VERSION ""

NS_ :

BS_:

BU_: Vector__XXX ECU SenderNode

BO_ 1039 ACC_MMI_R1: 5 Vector__XXX
 SG_ SelectedDistanceDisplayRequest : 1|2@0+ (1.0,0.0) [0|0] "" Vector__XXX
 SG_ DistanceOverrideDisplayRequest : 2|1@0+ (1.0,0.0) [0|0] "" Vector__XXX
 SG_ SpeedOverrideDisplayRequest : 3|1@0+ (1.0,0.0) [0|0] "" Vector__XXX
 SG_ ACCLSF_StatusDisplay : 7|4@0+ (1.0,0.0) [0|0] "" Vector__XXX
 SG_ ACCRequestedSpeedDisplayRequest : 15|8@0+ (1.0,0.0) [0|0] "" Vector__XXX
 SG_ DriverTakeOverDisplayRequest : 18|3@0+ (1.0,0.0) [0|0] "" Vector__XXX
 SG_ AEBS_FailureDisplayRequest : 19|1@0+ (1.0,0.0) [0|0] "" Vector__XXX
 SG_ AEBS_DangerAlert : 20|1@0+ (1.0,0.0) [0|0] "" Vector__XXX
 SG_ DetectedTargetDisplayRequest_TM : 23|3@0+ (1.0,0.0) [0|0] "" Vector__XXX
 SG_ DW_ActivationState_TM : 24|1@0+ (1.0,0.0) [0|0] "" Vector__XXX
 SG_ DW_FollowUpTimeDisplay_TM : 30|6@0+ (1.0,0.0) [0|0] "" Vector__XXX
 SG_ AEBS_DistanceWarning : 31|1@0+ (1.0,0.0) [0|0] "" Vector__XXX
 SG_ AEBS_TemporarlyFailureDisplay : 33|2@0+ (1.0,0.0) [0|0] "" Vector__XXX
 SG_ AEBS_PedestrianAlert : 35|2@0+ (1.0,0.0) [0|0] "" Vector__XXX
 SG_ SpeedNotRelevantDisplayRequest : 37|2@0+ (1.0,0.0) [0|0] "" Vector__XXX
 SG_ FollowUpTimeBlinkRequest_TM : 38|1@0+ (1.0,0.0) [0|0] "" Vector__XXX
 SG_ FCW_ActivationState : 39|1@0+ (1.0,0.0) [0|0] "" Vector__XXX

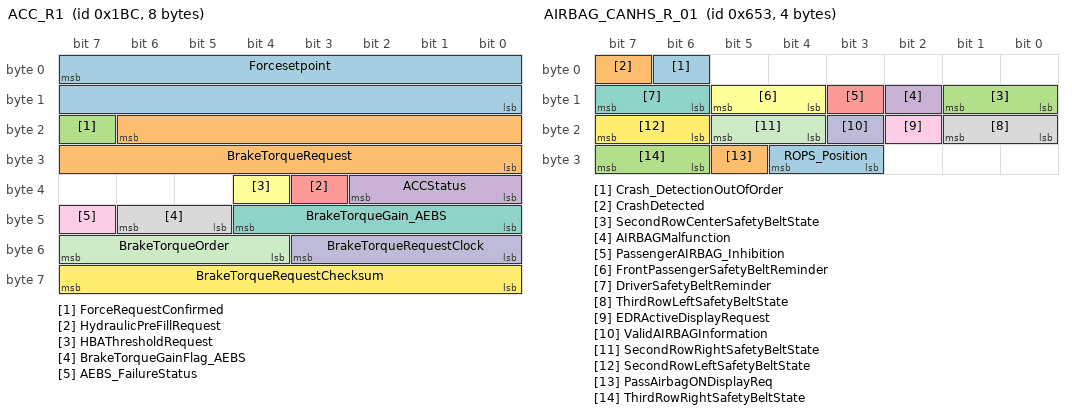
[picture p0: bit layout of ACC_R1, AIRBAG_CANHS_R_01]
BO_ 444 ACC_R1: 8 Vector__XXX
 SG_ Forcesetpoint : 7|16@0+ (1.0,0.0) [0|0] "" Vector__XXX
 SG_ BrakeTorqueRequest : 22|15@0+ (1.0,0.0) [0|0] "Nm" Vector__XXX
 SG_ ForceRequestConfirmed : 23|1@0+ (1.0,0.0) [0|0] "" Vector__XXX
 SG_ ACCStatus : 34|3@0+ (1.0,0.0) [0|0] "" Vector__XXX
 SG_ HydraulicPreFillRequest : 35|1@0+ (1.0,0.0) [0|0] "" Vector__XXX
 SG_ HBAThresholdRequest : 36|1@0+ (1.0,0.0) [0|0] "" Vector__XXX
 SG_ BrakeTorqueGain_AEBS : 44|5@0+ (0.05,1.0) [0|0] "" Vector__XXX
 SG_ BrakeTorqueGainFlag_AEBS : 46|2@0+ (1.0,0.0) [0|0] "" Vector__XXX
 SG_ AEBS_FailureStatus : 47|1@0+ (1.0,0.0) [0|0] "" Vector__XXX
 SG_ BrakeTorqueRequestClock : 51|4@0+ (1.0,0.0) [0|0] "" Vector__XXX
 SG_ BrakeTorqueOrder : 55|4@0+ (1.0,0.0) [0|0] "" Vector__XXX
 SG_ BrakeTorqueRequestChecksum : 63|8@0+ (1.0,0.0) [0|0] "" Vector__XXX

BO_ 1917 ACC_to_DTOOL: 8 Vector__XXX
 SG_ ACC_to_DTOOL : 7|64@0+ (1.0,0.0) [0|0] "" Vector__XXX

BO_ 35 AIRBAGCrash: 2 Vector__XXX
 SG_ AirbagCrashOrder : 7|16@0+ (1.0,0.0) [0|0] "" Vector__XXX

BO_ 1619 AIRBAG_CANHS_R_01: 4 Vector__XXX
 SG_ Crash_DetectionOutOfOrder : 6|1@0+ (1.0,0.0) [0|0] "" Vector__XXX
 SG_ CrashDetected : 7|1@0+ (1.0,0.0) [0|0] "" Vector__XXX
 SG_ SecondRowCenterSafetyBeltState : 9|2@0+ (1.0,0.0) [0|0] "" Vector__XXX
 SG_ AIRBAGMalfunction : 10|1@0+ (1.0,0.0) [0|0] "" Vector__XXX
 SG_ PassengerAIRBAG_Inhibition : 11|1@0+ (1.0,0.0) [0|0] "" Vector__XXX
 SG_ FrontPassengerSafetyBeltReminder : 13|2@0+ (1.0,0.0) [0|0] "" Vector__XXX
 SG_ DriverSafetyBeltReminder : 15|2@0+ (1.0,0.0) [0|0] "" Vector__XXX
 SG_ ThirdRowLeftSafetyBeltState : 17|2@0+ (1.0,0.0) [0|0] "" Vector__XXX
 SG_ EDRActiveDisplayRequest : 18|1@0+ (1.0,0.0) [0|0] "" Vector__XXX
 SG_ ValidAIRBAGInformation : 19|1@0+ (1.0,0.0) [0|0] "" Vector__XXX
 SG_ SecondRowRightSafetyBeltState : 21|2@0+ (1.0,0.0) [0|0] "" Vector__XXX
 SG_ SecondRowLeftSafetyBeltState : 23|2@0+ (1.0,0.0) [0|0] "" Vector__XXX
 SG_ ROPS_Position : 28|2@0+ (1.0,0.0) [0|0] "" Vector__XXX
 SG_ PassAirbagONDisplayReq : 29|1@0+ (1.0,0.0) [0|0] "" Vector__XXX
 SG_ ThirdRowRightSafetyBeltState : 31|2@0+ (1.0,0.0) [0|0] "" Vector__XXX

BO_ 1906 AIRBAG_to_DTOOL: 8 Vector__XXX
 SG_ AIRBAG_to_DTOOL : 7|64@0+ (1.0,0.0) [0|0] "" Vector__XXX

BO_ 1954 AMPLI_to_DTOOL: 8 Vector__XXX
 SG_ AMPLI_to_DTOOL : 7|64@0+ (1.0,0.0) [0|0] "" Vector__XXX

BO_ 2025 AT_to_DTOOL: 8 Vector__XXX
 SG_ AT_to_DTOOL : 7|64@0+ (1.0,0.0) [0|0] "" Vector__XXX

BO_ 1939 BCB_to_DTOOL: 8 Vector__XXX
 SG_ BCB_to_DTOOL : 7|64@0+ (1.0,0.0) [0|0] "" Vector__XXX

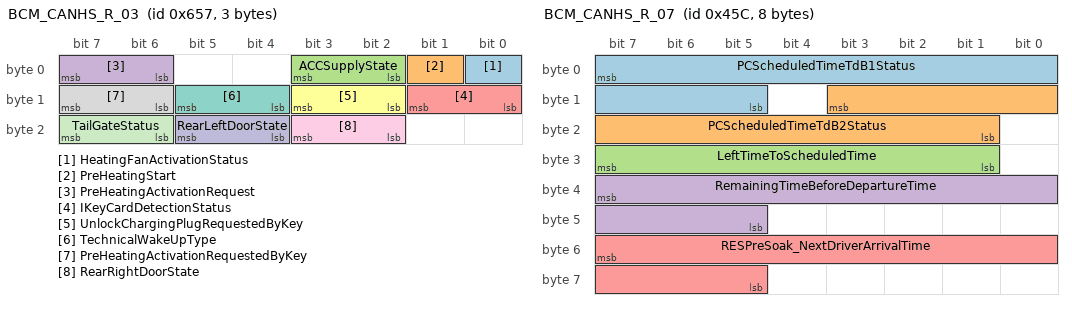
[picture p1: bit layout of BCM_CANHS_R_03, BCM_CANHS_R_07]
BO_ 1623 BCM_CANHS_R_03: 3 Vector__XXX
 SG_ HeatingFanActivationStatus : 0|1@0+ (1.0,0.0) [0|0] "" Vector__XXX
 SG_ PreHeatingStart : 1|1@0+ (1.0,0.0) [0|0] "" Vector__XXX
 SG_ ACCSupplyState : 3|2@0+ (1.0,0.0) [0|0] "" Vector__XXX
 SG_ PreHeatingActivationRequest : 7|2@0+ (1.0,0.0) [0|0] "" Vector__XXX
 SG_ IKeyCardDetectionStatus : 9|2@0+ (1.0,0.0) [0|0] "" Vector__XXX
 SG_ UnlockChargingPlugRequestedByKey : 11|2@0+ (1.0,0.0) [0|0] "" Vector__XXX
 SG_ TechnicalWakeUpType : 13|2@0+ (1.0,0.0) [0|0] "" Vector__XXX
 SG_ PreHeatingActivationRequestedByKey : 15|2@0+ (1.0,0.0) [0|0] "" Vector__XXX
 SG_ RearRightDoorState : 19|2@0+ (1.0,0.0) [0|0] "" Vector__XXX
 SG_ RearLeftDoorState : 21|2@0+ (1.0,0.0) [0|0] "" Vector__XXX
 SG_ TailGateStatus : 23|2@0+ (1.0,0.0) [0|0] "" Vector__XXX

BO_ 848 BCM_CANHS_R_04: 8 Vector__XXX
 SG_ VehicleStateExtented : 3|4@0+ (1.0,0.0) [0|0] "" Vector__XXX
 SG_ StartAutoSystemFailure : 5|2@0+ (1.0,0.0) [0|0] "" Vector__XXX
 SG_ BCM_WakeUpSleepCommand : 7|2@0+ (1.0,0.0) [0|0] "" Vector__XXX
 SG_ AbsoluteTimeSince1rstIgnition : 15|24@0+ (1.0,0.0) [0|0] "mn" Vector__XXX
 SG_ LightsRequest : 33|2@0+ (1.0,0.0) [0|0] "" Vector__XXX
 SG_ TailGateStatus : 35|2@0+ (1.0,0.0) [0|0] "" Vector__XXX
 SG_ TailGateButtonPushed : 37|2@0+ (1.0,0.0) [0|0] "" Vector__XXX
 SG_ FlashingIndicatorCommandPosition : 41|2@0+ (1.0,0.0) [0|0] "" Vector__XXX
 SG_ GenericApplicativeDiagEnable : 43|2@0+ (1.0,0.0) [0|0] "" Vector__XXX
 SG_ BrakeInfoStatus : 46|3@0+ (1.0,0.0) [0|0] "" Vector__XXX
 SG_ DiagMuxOn_BCM : 47|1@0+ (1.0,0.0) [0|0] "" Vector__XXX
 SG_ NeutralSwitchFaultDisplay : 48|1@0+ (1.0,0.0) [0|0] "" Vector__XXX
 SG_ VehicleOutsideLockedState : 49|1@0+ (1.0,0.0) [0|0] "" Vector__XXX
 SG_ PassengerDoorState : 51|2@0+ (1.0,0.0) [0|0] "" Vector__XXX
 SG_ DriverDoorState : 53|2@0+ (1.0,0.0) [0|0] "" Vector__XXX
 SG_ EngineHoodState : 55|2@0+ (1.0,0.0) [0|0] "" Vector__XXX
 SG_ RearRightDoorState : 57|2@0+ (1.0,0.0) [0|0] "" Vector__XXX
 SG_ RearLeftDoorState : 59|2@0+ (1.0,0.0) [0|0] "" Vector__XXX
 SG_ WarningLightsStatus : 60|1@0+ (1.0,0.0) [0|0] "" Vector__XXX
 SG_ WakeUpType : 61|1@0+ (1.0,0.0) [0|0] "" Vector__XXX
 SG_ EcoModeRequest : 63|2@0+ (1.0,0.0) [0|0] "" Vector__XXX

BO_ 1373 BCM_CANHS_R_05: 8 Vector__XXX
 SG_ Blower_StateBCM : 0|1@0+ (1.0,0.0) [0|0] "" Vector__XXX
 SG_ BrakeSwitchFailure : 2|2@0+ (1.0,0.0) [0|0] "" Vector__XXX
 SG_ ElectricalPowerDrived : 7|5@0+ (100.0,0.0) [0|0] "W" Vector__XXX
 SG_ FrontWashingRequest : 9|2@0+ (1.0,0.0) [0|0] "" Vector__XXX
 SG_ NeutralContact : 11|2@0+ (1.0,0.0) [0|0] "" Vector__XXX
 SG_ RearGearEngaged : 13|2@0+ (1.0,0.0) [0|0] "" Vector__XXX
 SG_ KeyVehicle : 15|2@0+ (1.0,0.0) [0|0] "" Vector__XXX
 SG_ PTC_Thermal_Regulator_Freeze : 16|1@0+ (1.0,0.0) [0|0] "" Vector__XXX
 SG_ PTCEngineIdleSpeedRequest : 17|1@0+ (1.0,0.0) [0|0] "" Vector__XXX
 SG_ DischargedBatTempoRequest : 18|1@0+ (1.0,0.0) [0|0] "" Vector__XXX
 SG_ RearDefrostEngaged : 19|1@0+ (1.0,0.0) [0|0] "" Vector__XXX
 SG_ ClutchSwitchMinimumTravel : 21|2@0+ (1.0,0.0) [0|0] "" Vector__XXX
 SG_ ClutchSwitchMaximumTravel : 23|2@0+ (1.0,0.0) [0|0] "" Vector__XXX
 SG_ MinimumVoltagebyBCM : 27|4@0+ (1.0,0.0) [0|0] "" Vector__XXX
 SG_ StarterStatus : 29|2@0+ (1.0,0.0) [0|0] "" Vector__XXX
 SG_ ParkingBrakeStatus : 31|2@0+ (1.0,0.0) [0|0] "" Vector__XXX
 SG_ CustomerDeparture : 33|2@0+ (1.0,0.0) [0|0] "" Vector__XXX
 SG_ PTCState : 35|2@0+ (1.0,0.0) [0|0] "" Vector__XXX
 SG_ AutoStartFailure : 37|2@0+ (1.0,0.0) [0|0] "" Vector__XXX
 SG_ StarterInhibtion : 39|2@0+ (1.0,0.0) [0|0] "" Vector__XXX
 SG_ DeliveryModeInformation_v2 : 41|2@0+ (1.0,0.0) [0|0] "" Vector__XXX
 SG_ FuelBurnerActivationState : 42|1@0+ (1.0,0.0) [0|0] "" Vector__XXX
 SG_ BCM_SailingIdleForbidden : 44|2@0+ (1.0,0.0) [0|0] "" Vector__XXX
 SG_ HighBeamState : 45|1@0+ (1.0,0.0) [0|0] "" Vector__XXX
 SG_ LowBeamState : 46|1@0+ (1.0,0.0) [0|0] "" Vector__XXX
 SG_ DisplayRequest : 47|1@0+ (1.0,0.0) [0|0] "" Vector__XXX
 SG_ ClimateCoolingRequest : 48|1@0+ (1.0,0.0) [0|0] "" Vector__XXX
 SG_ UserIdentification : 51|3@0+ (1.0,0.0) [0|0] "" Vector__XXX
 SG_ DayNightStatusSynth : 53|1@0+ (1.0,0.0) [0|0] "" Vector__XXX
 SG_ InternalLightingActivationState : 54|1@0+ (1.0,0.0) [0|0] "" Vector__XXX
 SG_ DeliveryModeInformation : 55|1@0+ (1.0,0.0) [0|0] "" Vector__XXX
 SG_ DriverDoorLockedStatus : 56|1@0+ (1.0,0.0) [0|0] "" Vector__XXX
 SG_ RKEButtonPressed : 60|4@0+ (1.0,0.0) [0|0] "" Vector__XXX
 SG_ FrontDefrostEngaged : 61|1@0+ (1.0,0.0) [0|0] "" Vector__XXX
 SG_ StartingRequest_EV : 63|2@0+ (1.0,0.0) [0|0] "" Vector__XXX

BO_ 1116 BCM_CANHS_R_07: 8 Vector__XXX
 SG_ PCScheduledTimeTdB1Status : 7|11@0+ (1.0,0.0) [0|0] "min" Vector__XXX
 SG_ PCScheduledTimeTdB2Status : 11|11@0+ (1.0,0.0) [0|0] "min" Vector__XXX
 SG_ LeftTimeToScheduledTime : 31|7@0+ (1.0,0.0) [0|0] "min" Vector__XXX
 SG_ RemainingTimeBeforeDepartureTime : 39|11@0+ (1.0,0.0) [0|0] "min" Vector__XXX
 SG_ RESPreSoak_NextDriverArrivalTime : 55|11@0+ (1.0,0.0) [0|0] "min" Vector__XXX

BO_ 1196 BCM_CANHS_R_08: 6 Vector__XXX
 SG_ GearboxChangeOnCrankingRequest : 1|2@0+ (1.0,0.0) [0|0] "" Vector__XXX
 SG_ Reserved_1bit : 2|1@0+ (1.0,0.0) [0|0] "" Vector__XXX
 SG_ DirectionSideConfirmation : 3|1@0+ (1.0,0.0) [0|0] "" Vector__XXX
 SG_ VehicleActivationState : 6|3@0+ (1.0,0.0) [0|0] "" Vector__XXX
 SG_ CustomerAutoStartWill : 7|1@0+ (1.0,0.0) [0|0] "" Vector__XXX
 SG_ BatteryVoltage_V2 : 15|8@0+ (0.06,6.0) [0|0] "V" Vector__XXX
 SG_ SOCBattery14V_BCM : 21|6@0+ (0.5,69.0) [0|0] "%" Vector__XXX
 SG_ BCM_StopAutoForbidden : 23|2@0+ (1.0,0.0) [0|0] "" Vector__XXX
 SG_ DriverDoorStatusSupposedFailure : 24|1@0+ (1.0,0.0) [0|0] "" Vector__XXX
 SG_ BattWarnReq_Level_Lo_BCM : 25|1@0+ (1.0,0.0) [0|0] "" Vector__XXX
 SG_ BattWarnReq_Level_Hi_BCM : 26|1@0+ (1.0,0.0) [0|0] "" Vector__XXX
 SG_ Battery14VCSensorFailureStatus : 27|1@0+ (1.0,0.0) [0|0] "" Vector__XXX
 SG_ StopStartSwitch : 29|2@0+ (1.0,0.0) [0|0] "" Vector__XXX
 SG_ BatterySetPointGeneratorStatus : 31|2@0+ (1.0,0.0) [0|0] "" Vector__XXX
 SG_ TailGateStatusSupposedFailure : 32|1@0+ (1.0,0.0) [0|0] "" Vector__XXX
 SG_ AuthorizationPH : 34|2@0+ (1.0,0.0) [0|0] "" Vector__XXX
 SG_ EEM_SailingIdleForbidden : 36|2@0+ (1.0,0.0) [0|0] "" Vector__XXX
 SG_ IgnitionSupplyConfirmation_BCM : 37|1@0+ (1.0,0.0) [0|0] "" Vector__XXX
 SG_ IdleSpeedInhibitionRequest_BCM : 39|2@0+ (1.0,0.0) [0|0] "" Vector__XXX
 SG_ HornRequest : 44|3@0+ (1.0,0.0) [0|0] "" Vector__XXX
 SG_ RemoteLight_BCM : 45|1@0+ (1.0,0.0) [0|0] "" Vector__XXX
 SG_ WindowsLiftAuthorization : 47|2@0+ (1.0,0.0) [0|0] "" Vector__XXX

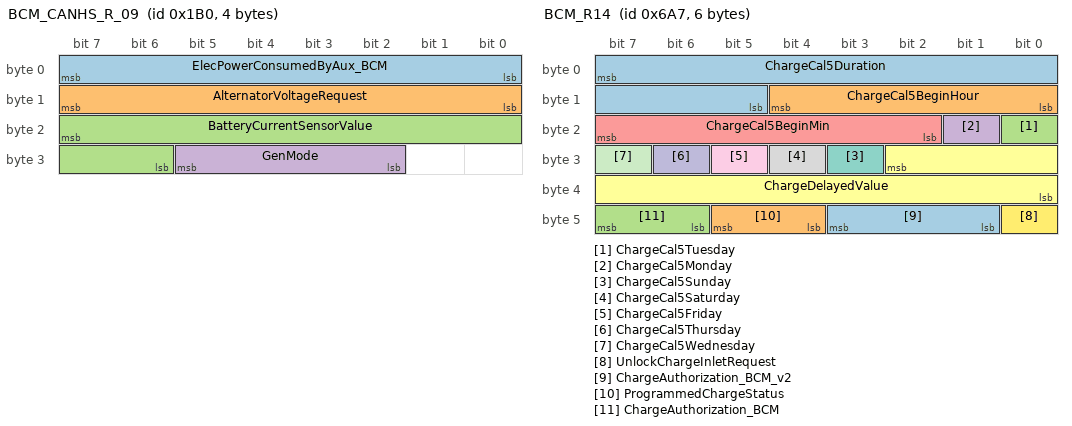
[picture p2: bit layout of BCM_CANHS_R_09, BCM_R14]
BO_ 432 BCM_CANHS_R_09: 4 Vector__XXX
 SG_ ElecPowerConsumedByAux_BCM : 7|8@0+ (40.0,0.0) [0|0] "W" Vector__XXX
 SG_ AlternatorVoltageRequest : 15|8@0+ (0.025,10.6) [0|0] "V" Vector__XXX
 SG_ BatteryCurrentSensorValue : 23|10@0- (1.0,-320.0) [0|0] "A" Vector__XXX
 SG_ GenMode : 29|4@0+ (1.0,0.0) [0|0] "" Vector__XXX

BO_ 1700 BCM_R12: 8 Vector__XXX
 SG_ ChargeCal1Duration : 7|11@0+ (1.0,0.0) [0|0] "min" Vector__XXX
 SG_ ChargeCal1BeginHour : 12|5@0+ (1.0,0.0) [0|0] "h" Vector__XXX
 SG_ ChargeCal1Tuesday : 16|1@0+ (1.0,0.0) [0|0] "" Vector__XXX
 SG_ ChargeCal1Monday : 17|1@0+ (1.0,0.0) [0|0] "" Vector__XXX
 SG_ ChargeCal1BeginMin : 23|6@0+ (1.0,0.0) [0|0] "min" Vector__XXX
 SG_ ZEnSwitchState : 26|1@0+ (1.0,0.0) [0|0] "" Vector__XXX
 SG_ ChargeCal1Sunday : 27|1@0+ (1.0,0.0) [0|0] "" Vector__XXX
 SG_ ChargeCal1Saturday : 28|1@0+ (1.0,0.0) [0|0] "" Vector__XXX
 SG_ ChargeCal1Friday : 29|1@0+ (1.0,0.0) [0|0] "" Vector__XXX
 SG_ ChargeCal1Thursday : 30|1@0+ (1.0,0.0) [0|0] "" Vector__XXX
 SG_ ChargeCal1Wednesday : 31|1@0+ (1.0,0.0) [0|0] "" Vector__XXX
 SG_ ChargeCal2Duration : 39|11@0+ (1.0,0.0) [0|0] "min" Vector__XXX
 SG_ ChargeCal2BeginHour : 44|5@0+ (1.0,0.0) [0|0] "h" Vector__XXX
 SG_ ChargeCal2Tuesday : 48|1@0+ (1.0,0.0) [0|0] "" Vector__XXX
 SG_ ChargeCal2Monday : 49|1@0+ (1.0,0.0) [0|0] "" Vector__XXX
 SG_ ChargeCal2BeginMin : 55|6@0+ (1.0,0.0) [0|0] "min" Vector__XXX
 SG_ ChargeCal2Sunday : 59|1@0+ (1.0,0.0) [0|0] "" Vector__XXX
 SG_ ChargeCal2Saturday : 60|1@0+ (1.0,0.0) [0|0] "" Vector__XXX
 SG_ ChargeCal2Friday : 61|1@0+ (1.0,0.0) [0|0] "" Vector__XXX
 SG_ ChargeCal2Thursday : 62|1@0+ (1.0,0.0) [0|0] "" Vector__XXX
 SG_ ChargeCal2Wednesday : 63|1@0+ (1.0,0.0) [0|0] "" Vector__XXX

BO_ 1702 BCM_R13: 8 Vector__XXX
 SG_ ChargeCal3Duration : 7|11@0+ (1.0,0.0) [0|0] "min" Vector__XXX
 SG_ ChargeCal3BeginHour : 12|5@0+ (1.0,0.0) [0|0] "h" Vector__XXX
 SG_ ChargeCal3Tuesday : 16|1@0+ (1.0,0.0) [0|0] "" Vector__XXX
 SG_ ChargeCal3Monday : 17|1@0+ (1.0,0.0) [0|0] "" Vector__XXX
 SG_ ChargeCal3BeginMin : 23|6@0+ (1.0,0.0) [0|0] "min" Vector__XXX
 SG_ ChargeCal3Sunday : 27|1@0+ (1.0,0.0) [0|0] "" Vector__XXX
 SG_ ChargeCal3Saturday : 28|1@0+ (1.0,0.0) [0|0] "" Vector__XXX
 SG_ ChargeCal3Friday : 29|1@0+ (1.0,0.0) [0|0] "" Vector__XXX
 SG_ ChargeCal3Thursday : 30|1@0+ (1.0,0.0) [0|0] "" Vector__XXX
 SG_ ChargeCal3Wednesday : 31|1@0+ (1.0,0.0) [0|0] "" Vector__XXX
 SG_ ChargeCal4Duration : 39|11@0+ (1.0,0.0) [0|0] "min" Vector__XXX
 SG_ ChargeCal4BeginHour : 44|5@0+ (1.0,0.0) [0|0] "h" Vector__XXX
 SG_ ChargeCal4Tuesday : 48|1@0+ (1.0,0.0) [0|0] "" Vector__XXX
 SG_ ChargeCal4Monday : 49|1@0+ (1.0,0.0) [0|0] "" Vector__XXX
 SG_ ChargeCal4BeginMin : 55|6@0+ (1.0,0.0) [0|0] "min" Vector__XXX
 SG_ ChargeCal4Sunday : 59|1@0+ (1.0,0.0) [0|0] "" Vector__XXX
 SG_ ChargeCal4Saturday : 60|1@0+ (1.0,0.0) [0|0] "" Vector__XXX
 SG_ ChargeCal4Friday : 61|1@0+ (1.0,0.0) [0|0] "" Vector__XXX
 SG_ ChargeCal4Thursday : 62|1@0+ (1.0,0.0) [0|0] "" Vector__XXX
 SG_ ChargeCal4Wednesday : 63|1@0+ (1.0,0.0) [0|0] "" Vector__XXX

BO_ 1703 BCM_R14: 6 Vector__XXX
 SG_ ChargeCal5Duration : 7|11@0+ (1.0,0.0) [0|0] "min" Vector__XXX
 SG_ ChargeCal5BeginHour : 12|5@0+ (1.0,0.0) [0|0] "h" Vector__XXX
 SG_ ChargeCal5Tuesday : 16|1@0+ (1.0,0.0) [0|0] "" Vector__XXX
 SG_ ChargeCal5Monday : 17|1@0+ (1.0,0.0) [0|0] "" Vector__XXX
 SG_ ChargeCal5BeginMin : 23|6@0+ (1.0,0.0) [0|0] "min" Vector__XXX
 SG_ ChargeDelayedValue : 26|11@0+ (1.0,0.0) [0|0] "min" Vector__XXX
 SG_ ChargeCal5Sunday : 27|1@0+ (1.0,0.0) [0|0] "" Vector__XXX
 SG_ ChargeCal5Saturday : 28|1@0+ (1.0,0.0) [0|0] "" Vector__XXX
 SG_ ChargeCal5Friday : 29|1@0+ (1.0,0.0) [0|0] "" Vector__XXX
 SG_ ChargeCal5Thursday : 30|1@0+ (1.0,0.0) [0|0] "" Vector__XXX
 SG_ ChargeCal5Wednesday : 31|1@0+ (1.0,0.0) [0|0] "" Vector__XXX
 SG_ UnlockChargeInletRequest : 40|1@0+ (1.0,0.0) [0|0] "" Vector__XXX
 SG_ ChargeAuthorization_BCM_v2 : 43|3@0+ (1.0,0.0) [0|0] "" Vector__XXX
 SG_ ProgrammedChargeStatus : 45|2@0+ (1.0,0.0) [0|0] "" Vector__XXX
 SG_ ChargeAuthorization_BCM : 47|2@0+ (1.0,0.0) [0|0] "" Vector__XXX

BO_ 1705 BCM_R15: 7 Vector__XXX
 SG_ PreSoakCal1ArrivalHour : 1|5@0+ (1.0,0.0) [0|0] "h" Vector__XXX
 SG_ PreSoakCal1ArrivalMin : 7|6@0+ (1.0,0.0) [0|0] "min" Vector__XXX
 SG_ PreSoakCal1Friday : 8|1@0+ (1.0,0.0) [0|0] "" Vector__XXX
 SG_ PreSoakCal1Thursday : 9|1@0+ (1.0,0.0) [0|0] "" Vector__XXX
 SG_ PreSoakCal1Wednesday : 10|1@0+ (1.0,0.0) [0|0] "" Vector__XXX
 SG_ PreSoakCal1Tuesday : 11|1@0+ (1.0,0.0) [0|0] "" Vector__XXX
 SG_ PreSoakCal1Monday : 12|1@0+ (1.0,0.0) [0|0] "" Vector__XXX
 SG_ PreSoakCal2ArrivalMin : 21|6@0+ (1.0,0.0) [0|0] "min" Vector__XXX
 SG_ PreSoakCal1Sunday : 22|1@0+ (1.0,0.0) [0|0] "" Vector__XXX
 SG_ PreSoakCal1Saturday : 23|1@0+ (1.0,0.0) [0|0] "" Vector__XXX
 SG_ PreSoakCal2Wednesday : 24|1@0+ (1.0,0.0) [0|0] "" Vector__XXX
 SG_ PreSoakCal2Tuesday : 25|1@0+ (1.0,0.0) [0|0] "" Vector__XXX
 SG_ PreSoakCal2Monday : 26|1@0+ (1.0,0.0) [0|0] "" Vector__XXX
 SG_ PreSoakCal2ArrivalHour : 31|5@0+ (1.0,0.0) [0|0] "h" Vector__XXX
 SG_ PreSoakCal3ArrivalMin : 35|6@0+ (1.0,0.0) [0|0] "min" Vector__XXX
 SG_ PreSoakCal2Sunday : 36|1@0+ (1.0,0.0) [0|0] "" Vector__XXX
 SG_ PreSoakCal2Saturday : 37|1@0+ (1.0,0.0) [0|0] "" Vector__XXX
 SG_ PreSoakCal2Friday : 38|1@0+ (1.0,0.0) [0|0] "" Vector__XXX
 SG_ PreSoakCal2Thursday : 39|1@0+ (1.0,0.0) [0|0] "" Vector__XXX
 SG_ PreSoakCal3Monday : 40|1@0+ (1.0,0.0) [0|0] "" Vector__XXX
 SG_ PreSoakCal3ArrivalHour : 45|5@0+ (1.0,0.0) [0|0] "h" Vector__XXX
 SG_ PreSoakCal3Sunday : 50|1@0+ (1.0,0.0) [0|0] "" Vector__XXX
 SG_ PreSoakCal3Saturday : 51|1@0+ (1.0,0.0) [0|0] "" Vector__XXX
 SG_ PreSoakCal3Friday : 52|1@0+ (1.0,0.0) [0|0] "" Vector__XXX
 SG_ PreSoakCal3Thursday : 53|1@0+ (1.0,0.0) [0|0] "" Vector__XXX
 SG_ PreSoakCal3Wednesday : 54|1@0+ (1.0,0.0) [0|0] "" Vector__XXX
 SG_ PreSoakCal3Tuesday : 55|1@0+ (1.0,0.0) [0|0] "" Vector__XXX

BO_ 1706 BCM_R16: 5 Vector__XXX
 SG_ PreSoakCal4ArrivalHour : 1|5@0+ (1.0,0.0) [0|0] "h" Vector__XXX
 SG_ PreSoakCal4ArrivalMin : 7|6@0+ (1.0,0.0) [0|0] "min" Vector__XXX
 SG_ PreSoakCal4Friday : 8|1@0+ (1.0,0.0) [0|0] "" Vector__XXX
 SG_ PreSoakCal4Thursday : 9|1@0+ (1.0,0.0) [0|0] "" Vector__XXX
 SG_ PreSoakCal4Wednesday : 10|1@0+ (1.0,0.0) [0|0] "" Vector__XXX
 SG_ PreSoakCal4Tuesday : 11|1@0+ (1.0,0.0) [0|0] "" Vector__XXX
 SG_ PreSoakCal4Monday : 12|1@0+ (1.0,0.0) [0|0] "" Vector__XXX
 SG_ PreSoakCal5ArrivalMin : 21|6@0+ (1.0,0.0) [0|0] "min" Vector__XXX
 SG_ PreSoakCal4Sunday : 22|1@0+ (1.0,0.0) [0|0] "" Vector__XXX
 SG_ PreSoakCal4Saturday : 23|1@0+ (1.0,0.0) [0|0] "" Vector__XXX
 SG_ PreSoakCal5Wednesday : 24|1@0+ (1.0,0.0) [0|0] "" Vector__XXX
 SG_ PreSoakCal5Tuesday : 25|1@0+ (1.0,0.0) [0|0] "" Vector__XXX
 SG_ PreSoakCal5Monday : 26|1@0+ (1.0,0.0) [0|0] "" Vector__XXX
 SG_ PreSoakCal5ArrivalHour : 31|5@0+ (1.0,0.0) [0|0] "h" Vector__XXX
 SG_ PreSoakCal5Sunday : 36|1@0+ (1.0,0.0) [0|0] "" Vector__XXX
 SG_ PreSoakCal5Saturday : 37|1@0+ (1.0,0.0) [0|0] "" Vector__XXX
 SG_ PreSoakCal5Friday : 38|1@0+ (1.0,0.0) [0|0] "" Vector__XXX
 SG_ PreSoakCal5Thursday : 39|1@0+ (1.0,0.0) [0|0] "" Vector__XXX

BO_ 1280 BCM_VERLOG: 5 Vector__XXX
 SG_ SLockValueControl : 4|5@0+ (1.0,0.0) [0|0] "" Vector__XXX
 SG_ SoftwareLockValue : 15|32@0+ (1.0,0.0) [0|0] "" Vector__XXX

BO_ 1893 BCM_to_DTOOL: 8 Vector__XXX
 SG_ BCM_to_DTOOL : 7|64@0+ (1.0,0.0) [0|0] "" Vector__XXX

BO_ 1844 BIC_to_DTOOL: 8 Vector__XXX
 SG_ BIC_to_DTOOL : 7|64@0+ (1.0,0.0) [0|0] "" Vector__XXX

BO_ 578 BRAKE_CANHS_RNr_01: 8 Vector__XXX
 SG_ MSRinRegulation : 0|1@0+ (1.0,0.0) [0|0] "" Vector__XXX
 SG_ AYCMalfunction : 1|1@0+ (1.0,0.0) [0|0] "" Vector__XXX
 SG_ AYCinRegulation : 2|1@0+ (1.0,0.0) [0|0] "" Vector__XXX
 SG_ HSAMalfunction : 3|1@0+ (1.0,0.0) [0|0] "" Vector__XXX
 SG_ ASRMalfunction : 4|1@0+ (1.0,0.0) [0|0] "" Vector__XXX
 SG_ ASRinRegulation : 5|1@0+ (1.0,0.0) [0|0] "" Vector__XXX
 SG_ ABSMalfunction : 6|1@0+ (1.0,0.0) [0|0] "" Vector__XXX
 SG_ ABSinRegulation : 7|1@0+ (1.0,0.0) [0|0] "" Vector__XXX
 SG_ ESP_TorqueControlType : 10|3@0+ (1.0,0.0) [0|0] "" Vector__XXX
 SG_ ESP_Clock : 14|4@0+ (1.0,0.0) [0|0] "" Vector__XXX
 SG_ MSRMalfunction : 15|1@0+ (1.0,0.0) [0|0] "" Vector__XXX
 SG_ ASRDynamicTorqueRequest : 23|12@0- (0.5,-400.0) [0|0] "Nm" Vector__XXX
 SG_ ASRStaticTorqueRequest : 27|12@0- (0.5,-400.0) [0|0] "Nm" Vector__XXX
 SG_ MSRTorqueRequest : 47|12@0- (0.5,-400.0) [0|0] "Nm" Vector__XXX
 SG_ HSA_ActivationState : 49|2@0+ (1.0,0.0) [0|0] "" Vector__XXX
 SG_ ShiftingAuthorization : 51|2@0+ (1.0,0.0) [0|0] "" Vector__XXX
 SG_ CRC_BRAKE_CANHS_RNr_01 : 63|8@0+ (1.0,0.0) [0|0] "" Vector__XXX

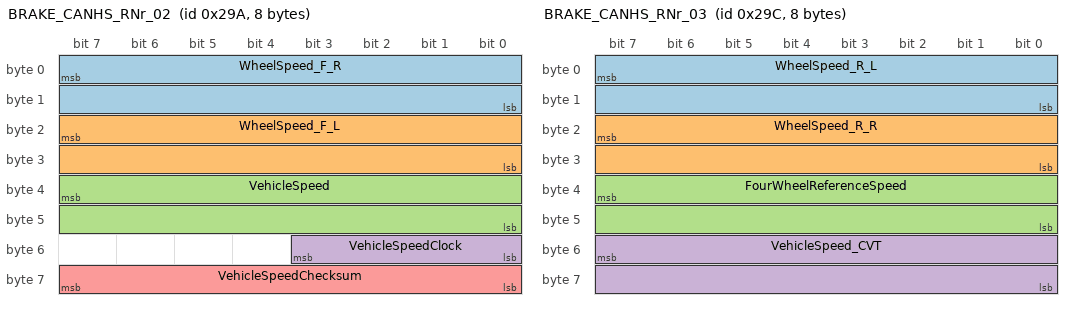
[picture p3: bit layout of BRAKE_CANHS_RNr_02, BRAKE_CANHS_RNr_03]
BO_ 666 BRAKE_CANHS_RNr_02: 8 Vector__XXX
 SG_ WheelSpeed_F_R : 7|16@0+ (0.0417,0.0) [0|0] "rpm" Vector__XXX
 SG_ WheelSpeed_F_L : 23|16@0+ (0.0417,0.0) [0|0] "rpm" Vector__XXX
 SG_ VehicleSpeed : 39|16@0+ (0.01,0.0) [0|0] "km/h" Vector__XXX
 SG_ VehicleSpeedClock : 51|4@0+ (1.0,0.0) [0|0] "" Vector__XXX
 SG_ VehicleSpeedChecksum : 63|8@0+ (1.0,0.0) [0|0] "" Vector__XXX

BO_ 668 BRAKE_CANHS_RNr_03: 8 Vector__XXX
 SG_ WheelSpeed_R_L : 7|16@0+ (0.0417,0.0) [0|0] "rpm" Vector__XXX
 SG_ WheelSpeed_R_R : 23|16@0+ (0.0417,0.0) [0|0] "rpm" Vector__XXX
 SG_ FourWheelReferenceSpeed : 39|16@0+ (0.01,0.0) [0|0] "km/h" Vector__XXX
 SG_ VehicleSpeed_CVT : 55|16@0+ (1.0,0.0) [0|0] "" Vector__XXX

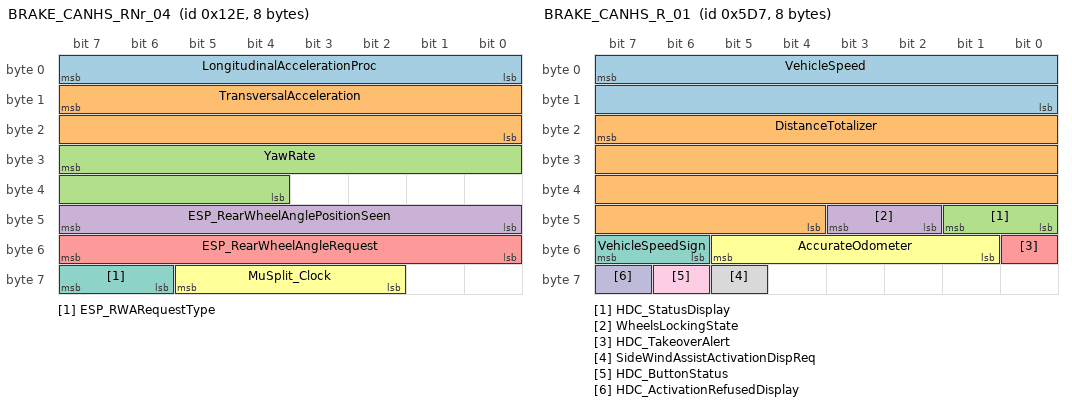
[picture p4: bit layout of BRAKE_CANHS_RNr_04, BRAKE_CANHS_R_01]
BO_ 302 BRAKE_CANHS_RNr_04: 8 Vector__XXX
 SG_ LongitudinalAccelerationProc : 7|8@0- (0.05,-10.0) [0|0] "m/s2" Vector__XXX
 SG_ TransversalAcceleration : 15|16@0- (0.004,-131.068) [0|0] "g" Vector__XXX
 SG_ YawRate : 31|12@0- (0.1,-204.7) [0|0] "°/s" Vector__XXX
 SG_ ESP_RearWheelAnglePositionSeen : 47|8@0+ (1.0,0.0) [0|0] "" Vector__XXX
 SG_ ESP_RearWheelAngleRequest : 55|8@0+ (1.0,0.0) [0|0] "" Vector__XXX
 SG_ MuSplit_Clock : 61|4@0+ (1.0,0.0) [0|0] "" Vector__XXX
 SG_ ESP_RWARequestType : 63|2@0+ (1.0,0.0) [0|0] "" Vector__XXX

BO_ 1495 BRAKE_CANHS_R_01: 8 Vector__XXX
 SG_ VehicleSpeed : 7|16@0+ (0.01,0.0) [0|0] "km/h" Vector__XXX
 SG_ DistanceTotalizer : 23|28@0+ (0.01,0.0) [0|0] "km" Vector__XXX
 SG_ HDC_StatusDisplay : 41|2@0+ (1.0,0.0) [0|0] "" Vector__XXX
 SG_ WheelsLockingState : 43|2@0+ (1.0,0.0) [0|0] "" Vector__XXX
 SG_ HDC_TakeoverAlert : 48|1@0+ (1.0,0.0) [0|0] "" Vector__XXX
 SG_ AccurateOdometer : 53|5@0+ (4.0,0.0) [0|0] "cm" Vector__XXX
 SG_ VehicleSpeedSign : 55|2@0+ (1.0,0.0) [0|0] "" Vector__XXX
 SG_ SideWindAssistActivationDispReq : 61|1@0+ (1.0,0.0) [0|0] "" Vector__XXX
 SG_ HDC_ButtonStatus : 62|1@0+ (1.0,0.0) [0|0] "" Vector__XXX
 SG_ HDC_ActivationRefusedDisplay : 63|1@0+ (1.0,0.0) [0|0] "" Vector__XXX

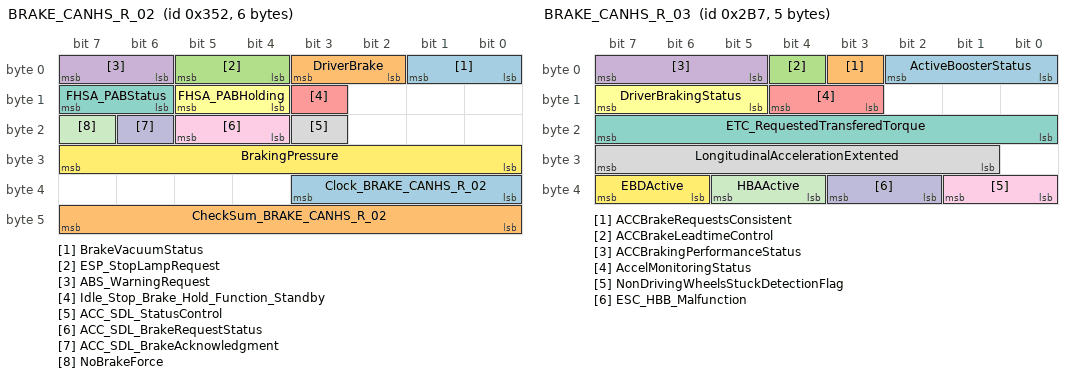
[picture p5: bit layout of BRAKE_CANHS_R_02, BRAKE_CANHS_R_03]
BO_ 850 BRAKE_CANHS_R_02: 6 Vector__XXX
 SG_ BrakeVacuumStatus : 1|2@0+ (1.0,0.0) [0|0] "" Vector__XXX
 SG_ DriverBrake : 3|2@0+ (1.0,0.0) [0|0] "" Vector__XXX
 SG_ ESP_StopLampRequest : 5|2@0+ (1.0,0.0) [0|0] "" Vector__XXX
 SG_ ABS_WarningRequest : 7|2@0+ (1.0,0.0) [0|0] "" Vector__XXX
 SG_ Idle_Stop_Brake_Hold_Function_Standby : 11|1@0+ (1.0,0.0) [0|0] "" Vector__XXX
 SG_ FHSA_PABHolding : 13|2@0+ (1.0,0.0) [0|0] "" Vector__XXX
 SG_ FHSA_PABStatus : 15|2@0+ (1.0,0.0) [0|0] "" Vector__XXX
 SG_ ACC_SDL_StatusControl : 19|1@0+ (1.0,0.0) [0|0] "" Vector__XXX
 SG_ ACC_SDL_BrakeRequestStatus : 21|2@0+ (1.0,0.0) [0|0] "" Vector__XXX
 SG_ ACC_SDL_BrakeAcknowledgment : 22|1@0+ (1.0,0.0) [0|0] "" Vector__XXX
 SG_ NoBrakeForce : 23|1@0+ (1.0,0.0) [0|0] "" Vector__XXX
 SG_ BrakingPressure : 31|8@0+ (1.0,0.0) [0|0] "" Vector__XXX
 SG_ Clock_BRAKE_CANHS_R_02 : 35|4@0+ (1.0,0.0) [0|0] "" Vector__XXX
 SG_ CheckSum_BRAKE_CANHS_R_02 : 47|8@0+ (1.0,0.0) [0|0] "" Vector__XXX

BO_ 695 BRAKE_CANHS_R_03: 5 Vector__XXX
 SG_ ActiveBoosterStatus : 2|3@0+ (1.0,0.0) [0|0] "" Vector__XXX
 SG_ ACCBrakeRequestsConsistent : 3|1@0+ (1.0,0.0) [0|0] "" Vector__XXX
 SG_ ACCBrakeLeadtimeControl : 4|1@0+ (1.0,0.0) [0|0] "" Vector__XXX
 SG_ ACCBrakingPerformanceStatus : 7|3@0+ (1.0,0.0) [0|0] "" Vector__XXX
 SG_ AccelMonitoringStatus : 12|2@0+ (1.0,0.0) [0|0] "" Vector__XXX
 SG_ DriverBrakingStatus : 15|3@0+ (1.0,0.0) [0|0] "" Vector__XXX
 SG_ ETC_RequestedTransferedTorque : 23|8@0+ (1.0,0.0) [0|0] "" Vector__XXX
 SG_ LongitudinalAccelerationExtented : 31|7@0+ (1.0,0.0) [0|0] "" Vector__XXX
 SG_ NonDrivingWheelsStuckDetectionFlag : 33|2@0+ (1.0,0.0) [0|0] "" Vector__XXX
 SG_ ESC_HBB_Malfunction : 35|2@0+ (1.0,0.0) [0|0] "" Vector__XXX
 SG_ HBAActive : 37|2@0+ (1.0,0.0) [0|0] "" Vector__XXX
 SG_ EBDActive : 39|2@0+ (1.0,0.0) [0|0] "" Vector__XXX

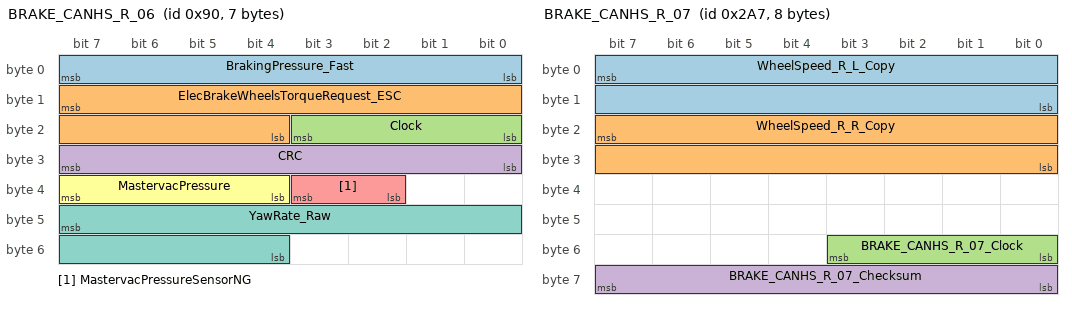
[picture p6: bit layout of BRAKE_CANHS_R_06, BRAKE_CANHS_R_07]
BO_ 144 BRAKE_CANHS_R_06: 7 Vector__XXX
 SG_ BrakingPressure_Fast : 7|8@0+ (0.5,0.0) [0|0] "bar" Vector__XXX
 SG_ ElecBrakeWheelsTorqueRequest_ESC : 15|12@0- (1.0,-4094.0) [0|0] "Nm" Vector__XXX
 SG_ Clock : 19|4@0+ (1.0,0.0) [0|0] "" Vector__XXX
 SG_ CRC : 31|8@0+ (1.0,0.0) [0|0] "" Vector__XXX
 SG_ MastervacPressureSensorNG : 35|2@0+ (1.0,0.0) [0|0] "" Vector__XXX
 SG_ MastervacPressure : 39|4@0+ (5.0,0.0) [0|0] "kPa" Vector__XXX
 SG_ YawRate_Raw : 47|12@0- (0.1,-204.7) [0|0] "°/s" Vector__XXX

BO_ 679 BRAKE_CANHS_R_07: 8 Vector__XXX
 SG_ WheelSpeed_R_L_Copy : 7|16@0+ (0.0417,0.0) [0|0] "rpm" Vector__XXX
 SG_ WheelSpeed_R_R_Copy : 23|16@0+ (0.0417,0.0) [0|0] "rpm" Vector__XXX
 SG_ BRAKE_CANHS_R_07_Clock : 51|4@0+ (1.0,0.0) [0|0] "" Vector__XXX
 SG_ BRAKE_CANHS_R_07_Checksum : 63|8@0+ (1.0,0.0) [0|0] "" Vector__XXX

BO_ 1888 BRAKE_to_DTOOL: 8 Vector__XXX
 SG_ Brake_to_DTOOL : 7|64@0+ (1.0,0.0) [0|0] "" Vector__XXX

BO_ 700 CAR_SHARING_BCM_01: 8 Vector__XXX
 SG_ CarSharingChallenge : 7|64@0+ (1.0,0.0) [0|0] "" Vector__XXX

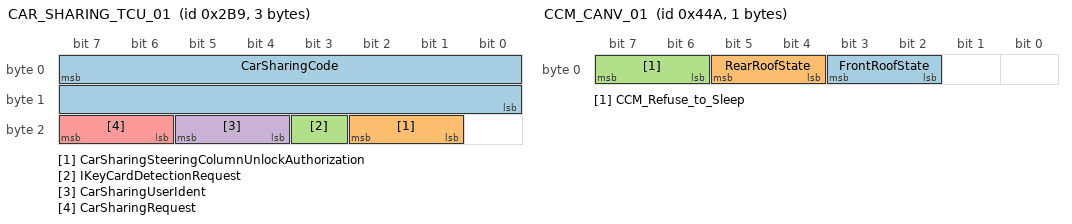
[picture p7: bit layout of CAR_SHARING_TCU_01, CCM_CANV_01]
BO_ 697 CAR_SHARING_TCU_01: 3 Vector__XXX
 SG_ CarSharingCode : 7|16@0+ (1.0,0.0) [0|0] "" Vector__XXX
 SG_ CarSharingSteeringColumnUnlockAuthorization : 18|2@0+ (1.0,0.0) [0|0] "" Vector__XXX
 SG_ IKeyCardDetectionRequest : 19|1@0+ (1.0,0.0) [0|0] "" Vector__XXX
 SG_ CarSharingUserIdent : 21|2@0+ (1.0,0.0) [0|0] "" Vector__XXX
 SG_ CarSharingRequest : 23|2@0+ (1.0,0.0) [0|0] "" Vector__XXX

BO_ 699 CAR_SHARING_TCU_02: 8 Vector__XXX
 SG_ CarSharingChallengeAnswer : 7|64@0+ (1.0,0.0) [0|0] "" Vector__XXX

BO_ 1098 CCM_CANV_01: 1 Vector__XXX
 SG_ FrontRoofState : 3|2@0+ (1.0,0.0) [0|0] "" Vector__XXX
 SG_ RearRoofState : 5|2@0+ (1.0,0.0) [0|0] "" Vector__XXX
 SG_ CCM_Refuse_to_Sleep : 7|2@0+ (1.0,0.0) [0|0] "" Vector__XXX

BO_ 1785 CGW_WakeUpFrame: 2 Vector__XXX
 SG_ CGW_WakeUp_Signal : 7|16@0+ (1.0,0.0) [0|0] "" Vector__XXX

BO_ 913 CLIM_CANHS_R_01: 7 Vector__XXX
 SG_ ACCompPowerUsed : 7|8@0+ (1.0,0.0) [0|0] "" Vector__XXX
 SG_ ClimateCoolingSelect : 8|1@0+ (1.0,0.0) [0|0] "" Vector__XXX
 SG_ ACCompValveRequest : 15|7@0+ (1.0,0.0) [0|0] "" Vector__XXX
 SG_ FrontDefrostRequest : 16|1@0+ (1.0,0.0) [0|0] "" Vector__XXX
 SG_ ACVbatTempoMaintain : 17|1@0+ (1.0,0.0) [0|0] "" Vector__XXX
 SG_ ACCompClutchRequest : 18|1@0+ (1.0,0.0) [0|0] "" Vector__XXX
 SG_ ACCompWorkingMode : 19|1@0+ (1.0,0.0) [0|0] "" Vector__XXX
 SG_ ACCompRequest : 20|1@0+ (1.0,0.0) [0|0] "" Vector__XXX
 SG_ ACCoolingFanSpeedRequest : 22|2@0+ (1.0,0.0) [0|0] "" Vector__XXX
 SG_ Blower_State : 23|1@0+ (1.0,0.0) [0|0] "" Vector__XXX
 SG_ PumpActivationRequest : 26|2@0+ (1.0,0.0) [0|0] "" Vector__XXX
 SG_ RearDefrostRequest : 27|1@0+ (1.0,0.0) [0|0] "" Vector__XXX
 SG_ FrontDefrostButtonState : 31|4@0+ (1.0,0.0) [0|0] "" Vector__XXX
 SG_ PTCNumberThermalRequest : 35|4@0+ (1.0,0.0) [0|0] "" Vector__XXX
 SG_ AC_StopAutoForbidden : 37|2@0+ (1.0,0.0) [0|0] "" Vector__XXX
 SG_ ClimCustomerAction : 39|2@0+ (1.0,0.0) [0|0] "" Vector__XXX
 SG_ MinimumVoltagebyAC : 43|4@0+ (1.0,0.0) [0|0] "" Vector__XXX
 SG_ ACMinEngineIdleSpeedRequest : 47|4@0+ (1.0,0.0) [0|0] "" Vector__XXX

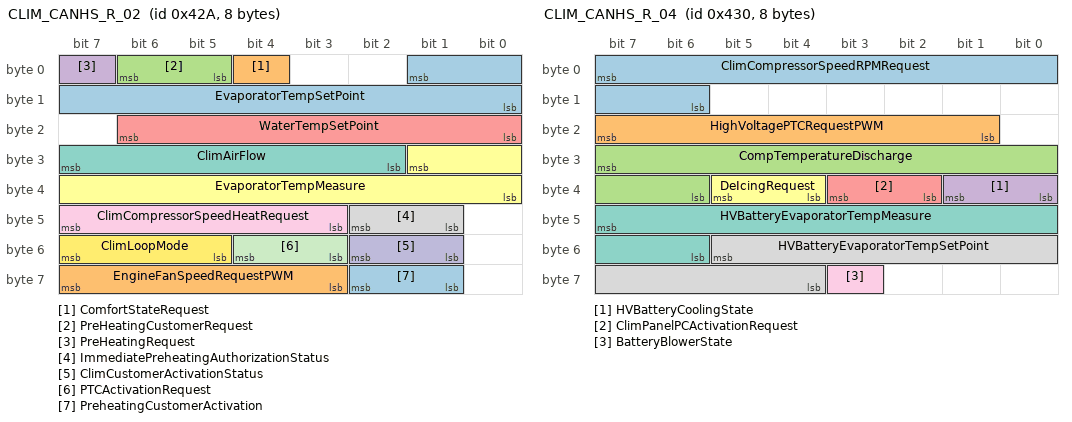
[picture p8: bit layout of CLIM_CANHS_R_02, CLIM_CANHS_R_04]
BO_ 1066 CLIM_CANHS_R_02: 8 Vector__XXX
 SG_ EvaporatorTempSetPoint : 1|10@0- (0.1,-40.0) [0|0] "°C" Vector__XXX
 SG_ ComfortStateRequest : 4|1@0+ (1.0,0.0) [0|0] "" Vector__XXX
 SG_ PreHeatingCustomerRequest : 6|2@0+ (1.0,0.0) [0|0] "" Vector__XXX
 SG_ PreHeatingRequest : 7|1@0+ (1.0,0.0) [0|0] "" Vector__XXX
 SG_ WaterTempSetPoint : 22|7@0+ (1.0,0.0) [0|0] "" Vector__XXX
 SG_ EvaporatorTempMeasure : 25|10@0- (0.1,-40.0) [0|0] "°C" Vector__XXX
 SG_ ClimAirFlow : 31|6@0+ (2.0,0.0) [0|0] "%" Vector__XXX
 SG_ ImmediatePreheatingAuthorizationStatus : 42|2@0+ (1.0,0.0) [0|0] "" Vector__XXX
 SG_ ClimCompressorSpeedHeatRequest : 47|5@0+ (1.0,0.0) [0|0] "" Vector__XXX
 SG_ ClimCustomerActivationStatus : 50|2@0+ (1.0,0.0) [0|0] "" Vector__XXX
 SG_ PTCActivationRequest : 52|2@0+ (1.0,0.0) [0|0] "" Vector__XXX
 SG_ ClimLoopMode : 55|3@0+ (1.0,0.0) [0|0] "" Vector__XXX
 SG_ PreheatingCustomerActivation : 58|2@0+ (1.0,0.0) [0|0] "" Vector__XXX
 SG_ EngineFanSpeedRequestPWM : 63|5@0+ (1.0,0.0) [0|0] "" Vector__XXX

BO_ 914 CLIM_CANHS_R_03: 7 Vector__XXX
 SG_ ACCompPowerUsed_V2 : 7|8@0+ (50.0,0.0) [0|0] "W" Vector__XXX
 SG_ AC_StopAutoForbidden : 9|2@0+ (1.0,0.0) [0|0] "" Vector__XXX
 SG_ PumpActivationRequest : 11|2@0+ (1.0,0.0) [0|0] "" Vector__XXX
 SG_ ACCoolingFanSpeedRequest : 13|2@0+ (1.0,0.0) [0|0] "" Vector__XXX
 SG_ Blower_State : 14|1@0+ (1.0,0.0) [0|0] "" Vector__XXX
 SG_ ACCompClutchStatus : 15|1@0+ (1.0,0.0) [0|0] "" Vector__XXX
 SG_ ACMinEngineIdleSpeedRequest : 19|4@0+ (1.0,0.0) [0|0] "" Vector__XXX
 SG_ PTCNumberThermalRequest : 23|4@0+ (1.0,0.0) [0|0] "" Vector__XXX
 SG_ RearDefrostRequest : 25|1@0+ (1.0,0.0) [0|0] "" Vector__XXX
 SG_ ACCompClutchRequest : 26|1@0+ (1.0,0.0) [0|0] "" Vector__XXX
 SG_ ACCompRequest : 27|1@0+ (1.0,0.0) [0|0] "" Vector__XXX
 SG_ MinimumVoltagebyAC : 31|4@0+ (1.0,0.0) [0|0] "" Vector__XXX
 SG_ AC_SailingIdleForbidden : 34|2@0+ (1.0,0.0) [0|0] "" Vector__XXX
 SG_ FrontDefrostRequest : 35|1@0+ (1.0,0.0) [0|0] "" Vector__XXX
 SG_ BatTempoDelayRequest_CLIM : 37|2@0+ (1.0,0.0) [0|0] "" Vector__XXX
 SG_ ChillerActivationStatus : 39|2@0+ (1.0,0.0) [0|0] "" Vector__XXX
 SG_ InternalTemp : 47|8@0- (1.0,-40.0) [0|0] "°C" Vector__XXX

BO_ 1072 CLIM_CANHS_R_04: 8 Vector__XXX
 SG_ ClimCompressorSpeedRPMRequest : 7|10@0+ (1.0,0.0) [0|0] "" Vector__XXX
 SG_ HighVoltagePTCRequestPWM : 23|7@0+ (1.0,0.0) [0|0] "%" Vector__XXX
 SG_ CompTemperatureDischarge : 31|10@0+ (1.0,0.0) [0|0] "" Vector__XXX
 SG_ HVBatteryCoolingState : 33|2@0+ (1.0,0.0) [0|0] "" Vector__XXX
 SG_ ClimPanelPCActivationRequest : 35|2@0+ (1.0,0.0) [0|0] "" Vector__XXX
 SG_ DeIcingRequest : 37|2@0+ (1.0,0.0) [0|0] "" Vector__XXX
 SG_ HVBatteryEvaporatorTempMeasure : 47|10@0+ (1.0,0.0) [0|0] "" Vector__XXX
 SG_ HVBatteryEvaporatorTempSetPoint : 53|10@0+ (1.0,0.0) [0|0] "" Vector__XXX
 SG_ BatteryBlowerState : 59|1@0+ (1.0,0.0) [0|0] "" Vector__XXX

BO_ 1892 CLIM_to_DTOOL: 8 Vector__XXX
 SG_ CLIM_to_DTOOL : 7|64@0+ (1.0,0.0) [0|0] "" Vector__XXX

BO_ 1272 CLUSTER_CANHS_RNr_01: 8 Vector__XXX
 SG_ OilDrainAlertResetRequest : 0|1@0+ (1.0,0.0) [0|0] "" Vector__XXX
 SG_ FuelLow : 1|1@0+ (1.0,0.0) [0|0] "" Vector__XXX
 SG_ HandBrakeSwitch : 3|2@0+ (1.0,0.0) [0|0] "" Vector__XXX
 SG_ DiagnosedFuelLow : 5|2@0+ (1.0,0.0) [0|0] "" Vector__XXX
 SG_ Cluster_Refuse_to_Sleep : 7|2@0+ (1.0,0.0) [0|0] "" Vector__XXX
 SG_ MuteRadioOrder : 9|2@0+ (1.0,0.0) [0|0] "" Vector__XXX
 SG_ DisplayedSpeedUnit : 10|1@0+ (1.0,0.0) [0|0] "" Vector__XXX
 SG_ ClusterDrivenLampsAutoCheck : 11|1@0+ (1.0,0.0) [0|0] "" Vector__XXX
 SG_ PassAIRBAGInhibitionLampState : 13|2@0+ (1.0,0.0) [0|0] "" Vector__XXX
 SG_ AIRBAGMalfunctionLampState : 15|2@0+ (1.0,0.0) [0|0] "" Vector__XXX
 SG_ BatteryChangedActivation : 21|2@0+ (1.0,0.0) [0|0] "" Vector__XXX
 SG_ PassAirbagONLampState : 23|2@0+ (1.0,0.0) [0|0] "" Vector__XXX
 SG_ DisplayedSpeed : 31|16@0+ (1.0,0.0) [0|0] "" Vector__XXX
 SG_ RawFuelGaugeResistance : 41|10@0+ (1.0,0.0) [0|0] "Ohm" Vector__XXX
 SG_ DayNightStatusForB_Switches : 43|1@0+ (1.0,0.0) [0|0] "" Vector__XXX
 SG_ DisplayFailure : 45|2@0+ (1.0,0.0) [0|0] "" Vector__XXX
 SG_ ACCDriverTakeOverDisplayAck : 46|1@0+ (1.0,0.0) [0|0] "" Vector__XXX
 SG_ ACCFrameMissing : 47|1@0+ (1.0,0.0) [0|0] "" Vector__XXX
 SG_ TachographPresence : 63|1@0+ (1.0,0.0) [0|0] "" Vector__XXX

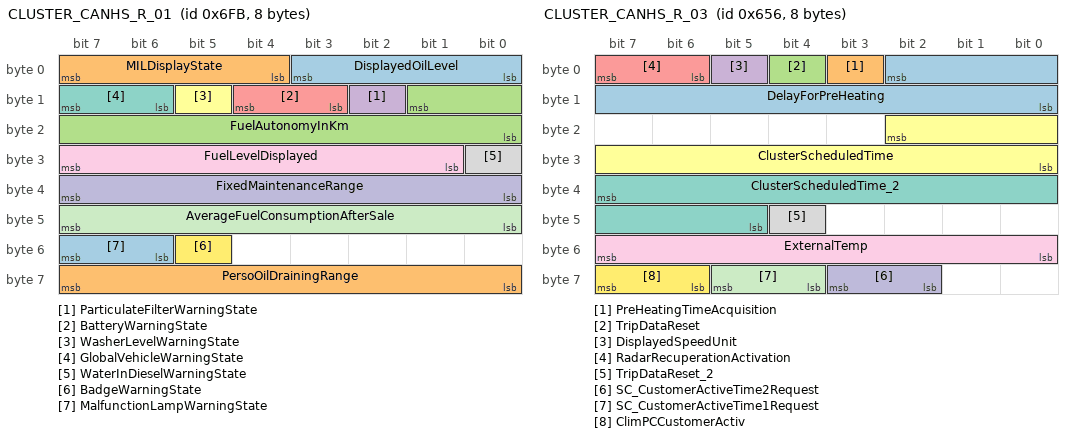
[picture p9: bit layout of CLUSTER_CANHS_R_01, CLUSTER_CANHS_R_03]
BO_ 1787 CLUSTER_CANHS_R_01: 8 Vector__XXX
 SG_ DisplayedOilLevel : 3|4@0+ (1.0,0.0) [0|0] "" Vector__XXX
 SG_ MILDisplayState : 7|4@0+ (1.0,0.0) [0|0] "" Vector__XXX
 SG_ FuelAutonomyInKm : 9|10@0+ (1.0,0.0) [0|0] "km" Vector__XXX
 SG_ ParticulateFilterWarningState : 10|1@0+ (1.0,0.0) [0|0] "" Vector__XXX
 SG_ BatteryWarningState : 12|2@0+ (1.0,0.0) [0|0] "" Vector__XXX
 SG_ WasherLevelWarningState : 13|1@0+ (1.0,0.0) [0|0] "" Vector__XXX
 SG_ GlobalVehicleWarningState : 15|2@0+ (1.0,0.0) [0|0] "" Vector__XXX
 SG_ WaterInDieselWarningState : 24|1@0+ (1.0,0.0) [0|0] "" Vector__XXX
 SG_ FuelLevelDisplayed : 31|7@0+ (1.0,0.0) [0|0] "l" Vector__XXX
 SG_ FixedMaintenanceRange : 39|8@0+ (250.0,0.0) [0|0] "km" Vector__XXX
 SG_ AverageFuelConsumptionAfterSale : 47|8@0+ (1.0,0.0) [0|0] "" Vector__XXX
 SG_ BadgeWarningState : 53|1@0+ (1.0,0.0) [0|0] "" Vector__XXX
 SG_ MalfunctionLampWarningState : 55|2@0+ (1.0,0.0) [0|0] "" Vector__XXX
 SG_ PersoOilDrainingRange : 63|8@0+ (250.0,0.0) [0|0] "km" Vector__XXX

BO_ 1489 CLUSTER_CANHS_R_02: 3 Vector__XXX
 SG_ MemorizedDistanceTotalizer : 7|24@0+ (1.0,0.0) [0|0] "km" Vector__XXX

BO_ 1622 CLUSTER_CANHS_R_03: 8 Vector__XXX
 SG_ DelayForPreHeating : 2|11@0+ (1.0,0.0) [0|0] "" Vector__XXX
 SG_ PreHeatingTimeAcquisition : 3|1@0+ (1.0,0.0) [0|0] "" Vector__XXX
 SG_ TripDataReset : 4|1@0+ (1.0,0.0) [0|0] "" Vector__XXX
 SG_ DisplayedSpeedUnit : 5|1@0+ (1.0,0.0) [0|0] "" Vector__XXX
 SG_ RadarRecuperationActivation : 7|2@0+ (1.0,0.0) [0|0] "" Vector__XXX
 SG_ ClusterScheduledTime : 18|11@0+ (1.0,0.0) [0|0] "min" Vector__XXX
 SG_ ClusterScheduledTime_2 : 39|11@0+ (1.0,0.0) [0|0] "min" Vector__XXX
 SG_ TripDataReset_2 : 44|1@0+ (1.0,0.0) [0|0] "" Vector__XXX
 SG_ ExternalTemp : 55|8@0+ (1.0,0.0) [0|0] "" Vector__XXX
 SG_ SC_CustomerActiveTime2Request : 59|2@0+ (1.0,0.0) [0|0] "" Vector__XXX
 SG_ SC_CustomerActiveTime1Request : 61|2@0+ (1.0,0.0) [0|0] "" Vector__XXX
 SG_ ClimPCCustomerActiv : 63|2@0+ (1.0,0.0) [0|0] "" Vector__XXX

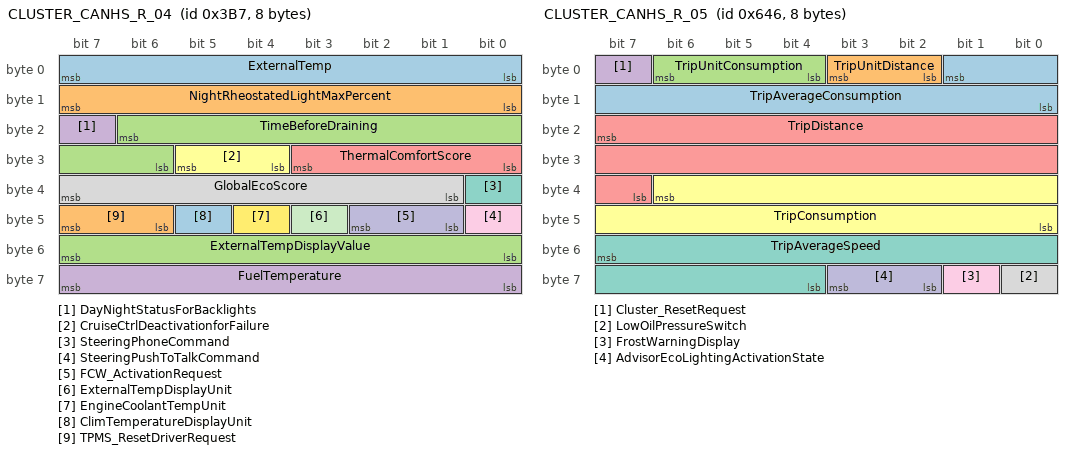
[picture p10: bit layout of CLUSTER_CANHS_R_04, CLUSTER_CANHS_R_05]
BO_ 951 CLUSTER_CANHS_R_04: 8 Vector__XXX
 SG_ ExternalTemp : 7|8@0+ (1.0,0.0) [0|0] "" Vector__XXX
 SG_ NightRheostatedLightMaxPercent : 15|8@0+ (0.4,0.0) [0|0] "%" Vector__XXX
 SG_ TimeBeforeDraining : 22|9@0+ (1.0,0.0) [0|0] "Day" Vector__XXX
 SG_ DayNightStatusForBacklights : 23|1@0+ (1.0,0.0) [0|0] "" Vector__XXX
 SG_ ThermalComfortScore : 27|4@0+ (1.0,0.0) [0|0] "" Vector__XXX
 SG_ CruiseCtrlDeactivationforFailure : 29|2@0+ (1.0,0.0) [0|0] "" Vector__XXX
 SG_ SteeringPhoneCommand : 32|1@0+ (1.0,0.0) [0|0] "" Vector__XXX
 SG_ GlobalEcoScore : 39|7@0+ (1.0,0.0) [0|0] "" Vector__XXX
 SG_ SteeringPushToTalkCommand : 40|1@0+ (1.0,0.0) [0|0] "" Vector__XXX
 SG_ FCW_ActivationRequest : 42|2@0+ (1.0,0.0) [0|0] "" Vector__XXX
 SG_ ExternalTempDisplayUnit : 43|1@0+ (1.0,0.0) [0|0] "" Vector__XXX
 SG_ EngineCoolantTempUnit : 44|1@0+ (1.0,0.0) [0|0] "" Vector__XXX
 SG_ ClimTemperatureDisplayUnit : 45|1@0+ (1.0,0.0) [0|0] "" Vector__XXX
 SG_ TPMS_ResetDriverRequest : 47|2@0+ (1.0,0.0) [0|0] "" Vector__XXX
 SG_ ExternalTempDisplayValue : 55|8@0- (1.0,-40.0) [0|0] "" Vector__XXX
 SG_ FuelTemperature : 63|8@0+ (1.0,0.0) [0|0] "" Vector__XXX

BO_ 1606 CLUSTER_CANHS_R_05: 8 Vector__XXX
 SG_ TripAverageConsumption : 1|10@0+ (0.1,0.0) [0|0] "" Vector__XXX
 SG_ TripUnitDistance : 3|2@0+ (1.0,0.0) [0|0] "" Vector__XXX
 SG_ TripUnitConsumption : 6|3@0+ (1.0,0.0) [0|0] "" Vector__XXX
 SG_ Cluster_ResetRequest : 7|1@0+ (1.0,0.0) [0|0] "" Vector__XXX
 SG_ TripDistance : 23|17@0+ (0.1,0.0) [0|0] "" Vector__XXX
 SG_ TripConsumption : 38|15@0+ (0.1,0.0) [0|0] "" Vector__XXX
 SG_ TripAverageSpeed : 55|12@0+ (0.1,0.0) [0|0] "" Vector__XXX
 SG_ LowOilPressureSwitch : 56|1@0+ (1.0,0.0) [0|0] "" Vector__XXX
 SG_ FrostWarningDisplay : 57|1@0+ (1.0,0.0) [0|0] "" Vector__XXX
 SG_ AdvisorEcoLightingActivationState : 59|2@0+ (1.0,0.0) [0|0] "" Vector__XXX

BO_ 1255 CLUSTER_CANHS_R_06: 2 Vector__XXX
 SG_ LocalTime : 7|11@0+ (1.0,0.0) [0|0] "min" Vector__XXX

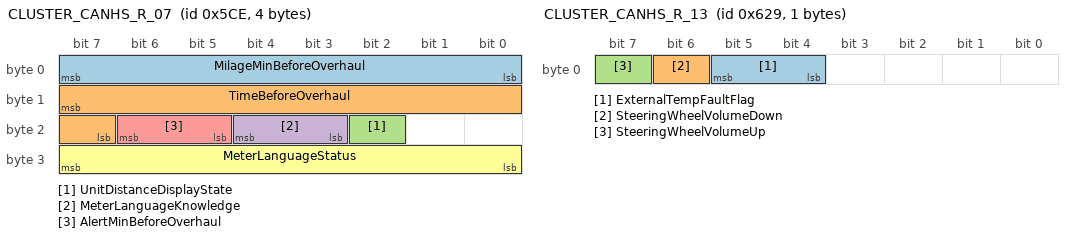
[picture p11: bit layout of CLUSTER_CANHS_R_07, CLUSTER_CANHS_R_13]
BO_ 1486 CLUSTER_CANHS_R_07: 4 Vector__XXX
 SG_ MilageMinBeforeOverhaul : 7|8@0+ (250.0,0.0) [0|0] "km" Vector__XXX
 SG_ TimeBeforeOverhaul : 15|9@0+ (1.0,0.0) [0|0] "Day" Vector__XXX
 SG_ UnitDistanceDisplayState : 18|1@0+ (1.0,0.0) [0|0] "" Vector__XXX
 SG_ MeterLanguageKnowledge : 20|2@0+ (1.0,0.0) [0|0] "" Vector__XXX
 SG_ AlertMinBeforeOverhaul : 22|2@0+ (1.0,0.0) [0|0] "" Vector__XXX
 SG_ MeterLanguageStatus : 31|8@0+ (1.0,0.0) [0|0] "" Vector__XXX

BO_ 1577 CLUSTER_CANHS_R_13: 1 Vector__XXX
 SG_ ExternalTempFaultFlag : 5|2@0+ (1.0,0.0) [0|0] "" Vector__XXX
 SG_ SteeringWheelVolumeDown : 6|1@0+ (1.0,0.0) [0|0] "" Vector__XXX
 SG_ SteeringWheelVolumeUp : 7|1@0+ (1.0,0.0) [0|0] "" Vector__XXX

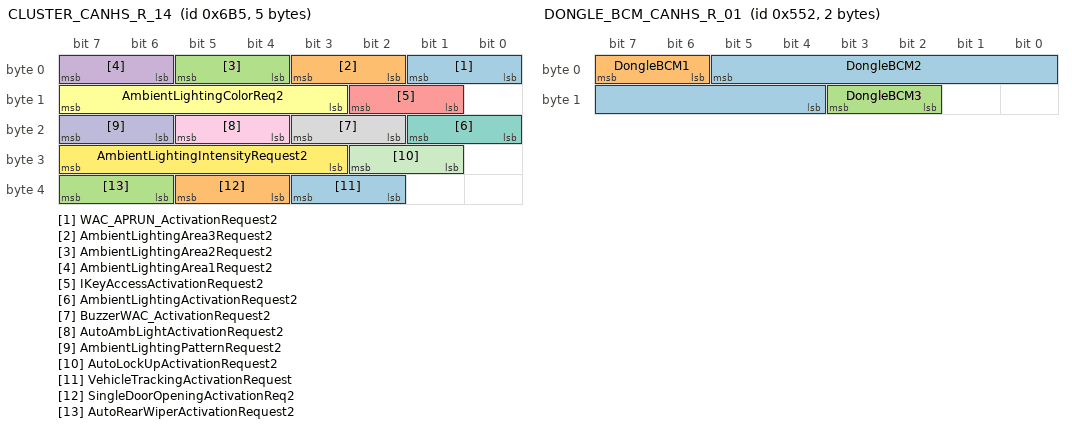
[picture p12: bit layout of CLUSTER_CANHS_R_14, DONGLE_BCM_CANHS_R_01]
BO_ 1717 CLUSTER_CANHS_R_14: 5 Vector__XXX
 SG_ WAC_APRUN_ActivationRequest2 : 1|2@0+ (1.0,0.0) [0|0] "" Vector__XXX
 SG_ AmbientLightingArea3Request2 : 3|2@0+ (1.0,0.0) [0|0] "" Vector__XXX
 SG_ AmbientLightingArea2Request2 : 5|2@0+ (1.0,0.0) [0|0] "" Vector__XXX
 SG_ AmbientLightingArea1Request2 : 7|2@0+ (1.0,0.0) [0|0] "" Vector__XXX
 SG_ IKeyAccessActivationRequest2 : 10|2@0+ (1.0,0.0) [0|0] "" Vector__XXX
 SG_ AmbientLightingColorReq2 : 15|5@0+ (1.0,0.0) [0|0] "" Vector__XXX
 SG_ AmbientLightingActivationRequest2 : 17|2@0+ (1.0,0.0) [0|0] "" Vector__XXX
 SG_ BuzzerWAC_ActivationRequest2 : 19|2@0+ (1.0,0.0) [0|0] "" Vector__XXX
 SG_ AutoAmbLightActivationRequest2 : 21|2@0+ (1.0,0.0) [0|0] "" Vector__XXX
 SG_ AmbientLightingPatternRequest2 : 23|2@0+ (1.0,0.0) [0|0] "" Vector__XXX
 SG_ AutoLockUpActivationRequest2 : 26|2@0+ (1.0,0.0) [0|0] "" Vector__XXX
 SG_ AmbientLightingIntensityRequest2 : 31|5@0+ (1.0,0.0) [0|0] "" Vector__XXX
 SG_ VehicleTrackingActivationRequest : 35|2@0+ (1.0,0.0) [0|0] "" Vector__XXX
 SG_ SingleDoorOpeningActivationReq2 : 37|2@0+ (1.0,0.0) [0|0] "" Vector__XXX
 SG_ AutoRearWiperActivationRequest2 : 39|2@0+ (1.0,0.0) [0|0] "" Vector__XXX

BO_ 1891 CLUSTER_to_DTOOL: 8 Vector__XXX
 SG_ CLUSTER_to_DTOOL : 7|64@0+ (1.0,0.0) [0|0] "" Vector__XXX

BO_ 1075 CONTROL_CANHS_R_01: 8 Vector__XXX
 SG_ AQMIoniserModeSelectionReq : 1|2@0+ (1.0,0.0) [0|0] "" Vector__XXX
 SG_ AQMFragDrawerUnlockRequest : 3|2@0+ (1.0,0.0) [0|0] "" Vector__XXX
 SG_ AQMFragSelectRequest : 7|3@0+ (1.0,0.0) [0|0] "" Vector__XXX
 SG_ ClimAQSActivationRequest : 9|2@0+ (1.0,0.0) [0|0] "" Vector__XXX
 SG_ AQMAutoRecyRequest : 11|2@0+ (1.0,0.0) [0|0] "" Vector__XXX
 SG_ AQMFragIntensityRequest : 15|4@0+ (1.0,0.0) [0|0] "" Vector__XXX
 SG_ ChargingTimerValueRequest : 22|7@0+ (1.0,0.0) [0|0] "" Vector__XXX
 SG_ MFD_ResetRequest : 23|1@0+ (1.0,0.0) [0|0] "" Vector__XXX
 SG_ SC_ActivationTime2Display : 24|1@0+ (1.0,0.0) [0|0] "" Vector__XXX
 SG_ SC_ActivationTime1Display : 25|1@0+ (1.0,0.0) [0|0] "" Vector__XXX
 SG_ IoniserAutoLaunchRequest : 27|2@0+ (1.0,0.0) [0|0] "" Vector__XXX
 SG_ ChargingTimerRequest : 29|2@0+ (1.0,0.0) [0|0] "" Vector__XXX
 SG_ ClimPCMMCCustomerActiv : 31|2@0+ (1.0,0.0) [0|0] "" Vector__XXX
 SG_ MMScheduledTime_1 : 39|11@0+ (1.0,0.0) [0|0] "" Vector__XXX
 SG_ MMScheduledTime_2 : 44|11@0+ (1.0,0.0) [0|0] "" Vector__XXX
 SG_ SC_ActivationTime1Display_V2 : 49|2@0+ (1.0,0.0) [0|0] "" Vector__XXX
 SG_ UserAcknowledgement : 58|1@0+ (1.0,0.0) [0|0] "" Vector__XXX
 SG_ HFP_SelectedManeuverTypeRequest : 61|3@0+ (1.0,0.0) [0|0] "" Vector__XXX
 SG_ SC_ActivationTime2Display_V2 : 63|2@0+ (1.0,0.0) [0|0] "" Vector__XXX

BO_ 2007 CSHV_to_DTOOL: 8 Vector__XXX
 SG_ CSHV_to_DTOOL : 7|64@0+ (1.0,0.0) [0|0] "" Vector__XXX

BO_ 1910 DCDC_to_DTOOL: 8 Vector__XXX
 SG_ DCDC_to_DTOOL : 7|64@0+ (1.0,0.0) [0|0] "" Vector__XXX

BO_ 1362 DONGLE_BCM_CANHS_R_01: 2 Vector__XXX
 SG_ DongleBCM2 : 5|10@0+ (1.0,0.0) [0|0] "" Vector__XXX
 SG_ DongleBCM1 : 7|2@0+ (1.0,0.0) [0|0] "" Vector__XXX
 SG_ DongleBCM3 : 11|2@0+ (1.0,0.0) [0|0] "" Vector__XXX

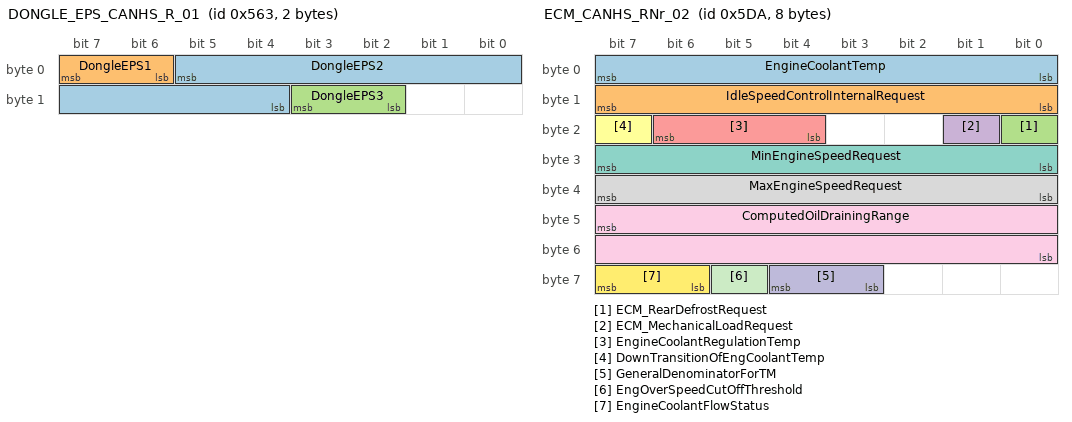
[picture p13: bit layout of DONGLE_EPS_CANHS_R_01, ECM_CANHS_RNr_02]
BO_ 1379 DONGLE_EPS_CANHS_R_01: 2 Vector__XXX
 SG_ DongleEPS2 : 5|10@0+ (1.0,0.0) [0|0] "" Vector__XXX
 SG_ DongleEPS1 : 7|2@0+ (1.0,0.0) [0|0] "" Vector__XXX
 SG_ DongleEPS3 : 11|2@0+ (1.0,0.0) [0|0] "" Vector__XXX

BO_ 1885 DTOOL_to_ACC: 8 Vector__XXX
 SG_ DTOOL_to_ACC : 7|64@0+ (1.0,0.0) [0|0] "" Vector__XXX

BO_ 1874 DTOOL_to_AIRBAG: 8 Vector__XXX
 SG_ DTOOL_to_AIRBAG : 7|64@0+ (1.0,0.0) [0|0] "" Vector__XXX

BO_ 2015 DTOOL_to_ALLUCEOBD: 8 Vector__XXX
 SG_ DTOOL_to_ALLUCEOBD : 7|64@0+ (1.0,0.0) [0|0] "" Vector__XXX

BO_ 1922 DTOOL_to_AMPLI: 8 Vector__XXX
 SG_ DTOOL_to_AMPLI : 7|64@0+ (1.0,0.0) [0|0] "" Vector__XXX

BO_ 2017 DTOOL_to_AT: 8 Vector__XXX
 SG_ DTOOL_to_AT : 7|64@0+ (1.0,0.0) [0|0] "" Vector__XXX

BO_ 1938 DTOOL_to_BCB: 8 Vector__XXX
 SG_ DTOOL_to_BCB : 7|64@0+ (1.0,0.0) [0|0] "" Vector__XXX

BO_ 1861 DTOOL_to_BCM: 8 Vector__XXX
 SG_ DTOOL_to_BCM : 7|64@0+ (1.0,0.0) [0|0] "" Vector__XXX

BO_ 1812 DTOOL_to_BIC: 8 Vector__XXX
 SG_ DTOOL_to_BIC : 7|64@0+ (1.0,0.0) [0|0] "" Vector__XXX

BO_ 1856 DTOOL_to_BRAKE: 8 Vector__XXX
 SG_ DTOOL_to_Brake : 7|64@0+ (1.0,0.0) [0|0] "" Vector__XXX

BO_ 1860 DTOOL_to_CLIM: 8 Vector__XXX
 SG_ DTOOL_to_CLIM : 7|64@0+ (1.0,0.0) [0|0] "" Vector__XXX

BO_ 1859 DTOOL_to_CLUSTER: 8 Vector__XXX
 SG_ DTOOL_to_CLUSTER : 7|64@0+ (1.0,0.0) [0|0] "" Vector__XXX

BO_ 1930 DTOOL_to_CSHV: 8 Vector__XXX
 SG_ DTOOL_to_CSHV : 7|64@0+ (1.0,0.0) [0|0] "" Vector__XXX

BO_ 1878 DTOOL_to_DCDC: 8 Vector__XXX
 SG_ DTOOL_to_DCDC : 7|64@0+ (1.0,0.0) [0|0] "" Vector__XXX

BO_ 2016 DTOOL_to_ECM: 8 Vector__XXX
 SG_ DTOOL_to_ECM : 7|64@0+ (1.0,0.0) [0|0] "" Vector__XXX

BO_ 1858 DTOOL_to_EPS: 8 Vector__XXX
 SG_ DTOOL_to_EPS : 7|64@0+ (1.0,0.0) [0|0] "" Vector__XXX

BO_ 2012 DTOOL_to_FRONT_CAMERA: 8 Vector__XXX
 SG_ DTOOL_to_FRONT_CAMERA : 7|64@0+ (1.0,0.0) [0|0] "" Vector__XXX

BO_ 1947 DTOOL_to_LBC: 8 Vector__XXX
 SG_ DTOOL_to_LBC : 7|64@0+ (1.0,0.0) [0|0] "" Vector__XXX

BO_ 1942 DTOOL_to_LBC2: 8 Vector__XXX
 SG_ DTOOL_to_LBC2 : 7|64@0+ (1.0,0.0) [0|0] "" Vector__XXX

BO_ 1794 DTOOL_to_LINSCH: 8 Vector__XXX
 SG_ DTOOL_to_LINSCH : 7|64@0+ (1.0,0.0) [0|0] "" Vector__XXX

BO_ 1863 DTOOL_to_NAV: 8 Vector__XXX
 SG_ DTOOL_to_NAV : 7|64@0+ (1.0,0.0) [0|0] "" Vector__XXX

BO_ 1882 DTOOL_to_PEB: 8 Vector__XXX
 SG_ DTOOL_to_PEB : 7|64@0+ (1.0,0.0) [0|0] "" Vector__XXX

BO_ 2008 DTOOL_to_PLGW: 8 Vector__XXX
 SG_ DTOOL_to_PLGW : 7|64@0+ (1.0,0.0) [0|0] "" Vector__XXX

BO_ 1867 DTOOL_to_ROOF: 8 Vector__XXX
 SG_ DTOOL_to_Roof : 7|64@0+ (1.0,0.0) [0|0] "" Vector__XXX

BO_ 1810 DTOOL_to_Radio: 8 Vector__XXX
 SG_ DTOOL_to_Radio : 7|64@0+ (1.0,0.0) [0|0] "" Vector__XXX

BO_ 1817 DTOOL_to_SACHA: 8 Vector__XXX
 SG_ DTOOL_to_SACHA : 7|64@0+ (1.0,0.0) [0|0] "" Vector__XXX

BO_ 2020 DTOOL_to_SCH: 8 Vector__XXX
 SG_ DTOOL_to_PEB : 7|64@0+ (1.0,0.0) [0|0] "" Vector__XXX

BO_ 1949 DTOOL_to_SHIFTER: 8 Vector__XXX
 SG_ DTOOL_to_SHIFTER : 7|64@0+ (1.0,0.0) [0|0] "" Vector__XXX

BO_ 1994 DTOOL_to_TCU: 8 Vector__XXX
 SG_ DTOOL_to_TCU : 7|64@0+ (1.0,0.0) [0|0] "" Vector__XXX

BO_ 1869 DTOOL_to_USM: 8 Vector__XXX
 SG_ DTOOL_to_USM : 7|64@0+ (1.0,0.0) [0|0] "" Vector__XXX

BO_ 1855 DTOOL_to_VSP: 8 Vector__XXX
 SG_ DTOOL_to_VSP : 7|64@0+ (1.0,0.0) [0|0] "" Vector__XXX

BO_ 1990 DTOOL_to_WSU: 8 Vector__XXX
 SG_ DTOOL_to_WSU : 7|64@0+ (1.0,0.0) [0|0] "" Vector__XXX

BO_ 502 ECM_CANHS_RNr_01: 8 Vector__XXX
 SG_ MaxElectricalPowerAllowed : 4|5@0+ (100.0,0.0) [0|0] "W" Vector__XXX
 SG_ EmissionN_IdleRequest : 5|1@0+ (1.0,0.0) [0|0] "" Vector__XXX
 SG_ EngineFanSpeedRequest : 7|2@0+ (1.0,0.0) [0|0] "" Vector__XXX
 SG_ EngineStopRequestOrigine : 11|4@0+ (1.0,0.0) [0|0] "" Vector__XXX
 SG_ EngineStatus_R : 13|2@0+ (1.0,0.0) [0|0] "" Vector__XXX
 SG_ ElectricalPowerCutFreeze : 15|2@0+ (1.0,0.0) [0|0] "" Vector__XXX
 SG_ ACHighPressureSensor : 16|9@0+ (0.1,0.0) [0|0] "bar" Vector__XXX
 SG_ ACCompAuthorized : 17|1@0+ (1.0,0.0) [0|0] "" Vector__XXX
 SG_ N_IdleInstructionSignal : 18|1@0+ (1.0,0.0) [0|0] "" Vector__XXX
 SG_ OpenActiveBrakeSwitch_ECM : 20|2@0+ (1.0,0.0) [0|0] "" Vector__XXX
 SG_ ACCompClutchActivation : 21|1@0+ (1.0,0.0) [0|0] "" Vector__XXX
 SG_ CrankingAuthorization_ECM : 23|2@0+ (1.0,0.0) [0|0] "" Vector__XXX
 SG_ RST_RESERVED_2b : 33|2@0+ (1.0,0.0) [0|0] "" Vector__XXX
 SG_ Reserved_2bits : 35|2@0+ (1.0,0.0) [0|0] "" Vector__XXX
 SG_ DMSOrder : 37|2@0+ (1.0,0.0) [0|0] "" Vector__XXX
 SG_ FloatingInhibition : 39|2@0+ (1.0,0.0) [0|0] "" Vector__XXX
 SG_ AllowedPowerGradient : 47|8@0+ (1.0,0.0) [0|0] "" Vector__XXX
 SG_ AlternatorMaximumPower : 55|8@0+ (1.0,0.0) [0|0] "" Vector__XXX
 SG_ ACCompMaximumPower : 63|8@0+ (25.0,0.0) [0|0] "Watts" Vector__XXX

BO_ 1498 ECM_CANHS_RNr_02: 8 Vector__XXX
 SG_ EngineCoolantTemp : 7|8@0- (1.0,-40.0) [0|0] "°C" Vector__XXX
 SG_ IdleSpeedControlInternalRequest : 15|8@0+ (8.0,0.0) [0|0] "tr/mn" Vector__XXX
 SG_ ECM_RearDefrostRequest : 16|1@0+ (1.0,0.0) [0|0] "" Vector__XXX
 SG_ ECM_MechanicalLoadRequest : 17|1@0+ (1.0,0.0) [0|0] "" Vector__XXX
 SG_ EngineCoolantRegulationTemp : 22|3@0+ (1.0,0.0) [0|0] "" Vector__XXX
 SG_ DownTransitionOfEngCoolantTemp : 23|1@0+ (1.0,0.0) [0|0] "" Vector__XXX
 SG_ MinEngineSpeedRequest : 31|8@0+ (1.0,0.0) [0|0] "" Vector__XXX
 SG_ MaxEngineSpeedRequest : 39|8@0+ (32.0,0.0) [0|0] "rpm" Vector__XXX
 SG_ ComputedOilDrainingRange : 47|16@0+ (1.0,0.0) [0|0] "km" Vector__XXX
 SG_ GeneralDenominatorForTM : 60|2@0+ (1.0,0.0) [0|0] "" Vector__XXX
 SG_ EngOverSpeedCutOffThreshold : 61|1@0+ (1.0,0.0) [0|0] "" Vector__XXX
 SG_ EngineCoolantFlowStatus : 63|2@0+ (1.0,0.0) [0|0] "" Vector__XXX

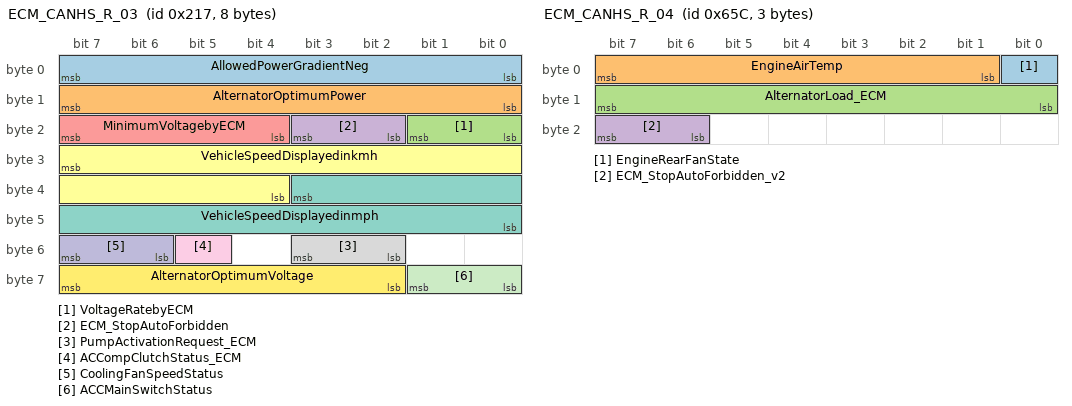
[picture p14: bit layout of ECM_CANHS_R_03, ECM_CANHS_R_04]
BO_ 535 ECM_CANHS_R_03: 8 Vector__XXX
 SG_ AllowedPowerGradientNeg : 7|8@0+ (1.0,0.0) [0|0] "" Vector__XXX
 SG_ AlternatorOptimumPower : 15|8@0+ (1.0,0.0) [0|0] "" Vector__XXX
 SG_ VoltageRatebyECM : 17|2@0+ (1.0,0.0) [0|0] "" Vector__XXX
 SG_ ECM_StopAutoForbidden : 19|2@0+ (1.0,0.0) [0|0] "" Vector__XXX
 SG_ MinimumVoltagebyECM : 23|4@0+ (0.25,11.5) [0|0] "V" Vector__XXX
 SG_ VehicleSpeedDisplayedinkmh : 31|12@0+ (0.1,0.0) [0|0] "km/h" Vector__XXX
 SG_ VehicleSpeedDisplayedinmph : 35|12@0+ (0.1,0.0) [0|0] "m/h" Vector__XXX
 SG_ PumpActivationRequest_ECM : 51|2@0+ (1.0,0.0) [0|0] "" Vector__XXX
 SG_ ACCompClutchStatus_ECM : 53|1@0+ (1.0,0.0) [0|0] "" Vector__XXX
 SG_ CoolingFanSpeedStatus : 55|2@0+ (1.0,0.0) [0|0] "" Vector__XXX
 SG_ ACCMainSwitchStatus : 57|2@0+ (1.0,0.0) [0|0] "" Vector__XXX
 SG_ AlternatorOptimumVoltage : 63|6@0+ (0.1,10.6) [0|0] "V" Vector__XXX

BO_ 1628 ECM_CANHS_R_04: 3 Vector__XXX
 SG_ EngineRearFanState : 0|1@0+ (1.0,0.0) [0|0] "" Vector__XXX
 SG_ EngineAirTemp : 7|7@0- (1.0,-40.0) [0|0] "°C" Vector__XXX
 SG_ AlternatorLoad_ECM : 15|8@0+ (0.390625,0.0) [0|0] "%" Vector__XXX
 SG_ ECM_StopAutoForbidden_v2 : 23|2@0+ (1.0,0.0) [0|0] "" Vector__XXX

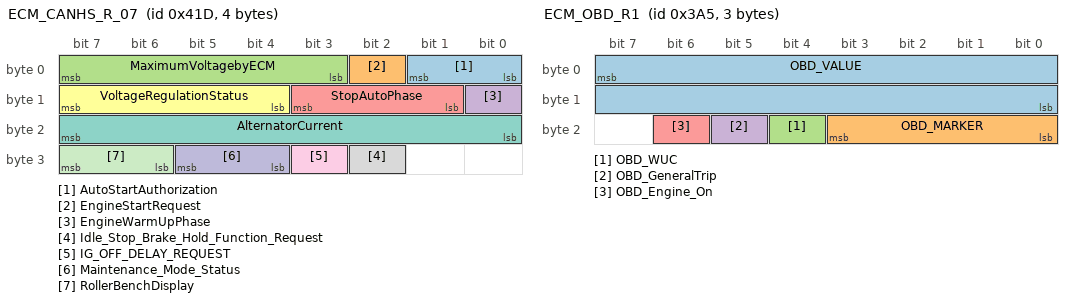
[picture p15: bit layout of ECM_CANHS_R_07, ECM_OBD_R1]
BO_ 1053 ECM_CANHS_R_07: 4 Vector__XXX
 SG_ AutoStartAuthorization : 1|2@0+ (1.0,0.0) [0|0] "" Vector__XXX
 SG_ EngineStartRequest : 2|1@0+ (1.0,0.0) [0|0] "" Vector__XXX
 SG_ MaximumVoltagebyECM : 7|5@0+ (0.1,12.0) [0|0] "V" Vector__XXX
 SG_ EngineWarmUpPhase : 8|1@0+ (1.0,0.0) [0|0] "" Vector__XXX
 SG_ StopAutoPhase : 11|3@0+ (1.0,0.0) [0|0] "" Vector__XXX
 SG_ VoltageRegulationStatus : 15|4@0+ (1.0,0.0) [0|0] "" Vector__XXX
 SG_ AlternatorCurrent : 23|8@0+ (2.0,0.0) [0|0] "A" Vector__XXX
 SG_ Idle_Stop_Brake_Hold_Function_Request : 26|1@0+ (1.0,0.0) [0|0] "" Vector__XXX
 SG_ IG_OFF_DELAY_REQUEST : 27|1@0+ (1.0,0.0) [0|0] "" Vector__XXX
 SG_ Maintenance_Mode_Status : 29|2@0+ (1.0,0.0) [0|0] "" Vector__XXX
 SG_ RollerBenchDisplay : 31|2@0+ (1.0,0.0) [0|0] "" Vector__XXX

BO_ 878 ECM_INIT_INFO_RN1: 4 Vector__XXX
 SG_ StarterActivationCounter : 7|16@0+ (10.0,0.0) [0|0] "" Vector__XXX
 SG_ HPPumpActivationCounter : 23|16@0+ (10.0,0.0) [0|0] "" Vector__XXX

BO_ 933 ECM_OBD_R1: 3 Vector__XXX
 SG_ OBD_VALUE : 7|16@0+ (1.0,0.0) [0|0] "" Vector__XXX
 SG_ OBD_MARKER : 19|4@0+ (1.0,0.0) [0|0] "Ah" Vector__XXX
 SG_ OBD_WUC : 20|1@0+ (1.0,0.0) [0|0] "" Vector__XXX
 SG_ OBD_GeneralTrip : 21|1@0+ (1.0,0.0) [0|0] "" Vector__XXX
 SG_ OBD_Engine_On : 22|1@0+ (1.0,0.0) [0|0] "" Vector__XXX

BO_ 1297 ECM_VERLOG: 7 Vector__XXX
 SG_ SLockRequestControl : 3|4@0+ (1.0,0.0) [0|0] "" Vector__XXX
 SG_ SoftwareLockRequest : 15|48@0+ (1.0,0.0) [0|0] "" Vector__XXX

BO_ 2024 ECM_to_DTOOL: 8 Vector__XXX
 SG_ ECM_to_DTOOL : 7|64@0+ (1.0,0.0) [0|0] "" Vector__XXX

BO_ 529 EMM_CANHS_R_01: 8 Vector__XXX
 SG_ IdleSpeedInhibitionRequest : 1|2@0+ (1.0,0.0) [0|0] "" Vector__XXX
 SG_ IgnitionSupplyConfirmation : 2|1@0+ (1.0,0.0) [0|0] "" Vector__XXX
 SG_ IgnitionControlState : 3|1@0+ (1.0,0.0) [0|0] "" Vector__XXX
 SG_ PositionLightsOmissionWarningEMM : 5|2@0+ (1.0,0.0) [0|0] "" Vector__XXX
 SG_ EMM_Refuse_to_Sleep : 7|2@0+ (1.0,0.0) [0|0] "" Vector__XXX
 SG_ SharpInstantMecanicalPowerByAlt : 15|8@0+ (1.0,0.0) [0|0] "" Vector__XXX
 SG_ ElecPowerConsumedByAux : 23|8@0+ (1.0,0.0) [0|0] "" Vector__XXX
 SG_ AlternatorLoad : 31|8@0+ (1.0,0.0) [0|0] "" Vector__XXX
 SG_ FrontWiperStatus : 33|2@0+ (1.0,0.0) [0|0] "" Vector__XXX
 SG_ SOCBattery14V : 39|6@0+ (1.0,0.0) [0|0] "" Vector__XXX
 SG_ EngineStopAutoWarnStatus : 40|1@0+ (1.0,0.0) [0|0] "" Vector__XXX
 SG_ RemoteLightingRequest : 42|2@0+ (1.0,0.0) [0|0] "" Vector__XXX
 SG_ LowBeamDisplayEMM : 43|1@0+ (1.0,0.0) [0|0] "" Vector__XXX
 SG_ HighBeamDisplayEMM : 44|1@0+ (1.0,0.0) [0|0] "" Vector__XXX
 SG_ PositionLightsDisplayEMM : 45|1@0+ (1.0,0.0) [0|0] "" Vector__XXX
 SG_ FrontFogLightsDisplayEMM : 46|1@0+ (1.0,0.0) [0|0] "" Vector__XXX
 SG_ RearFogLightStateDisplayEMM : 47|1@0+ (1.0,0.0) [0|0] "" Vector__XXX
 SG_ EMM_DayNightStatusSynthesis : 53|2@0+ (1.0,0.0) [0|0] "" Vector__XXX
 SG_ MiniConsumptionRequest : 55|2@0+ (1.0,0.0) [0|0] "" Vector__XXX
 SG_ BatteryVoltage : 63|8@0+ (0.0625,0.0) [0|0] "V" Vector__XXX

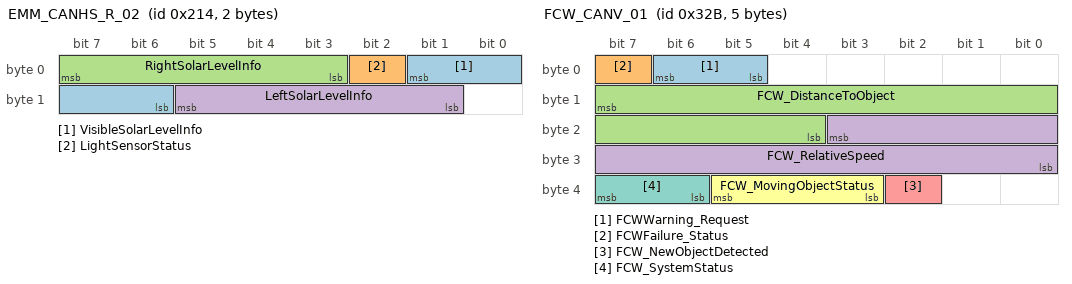
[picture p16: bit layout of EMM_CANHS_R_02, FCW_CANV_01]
BO_ 532 EMM_CANHS_R_02: 2 Vector__XXX
 SG_ VisibleSolarLevelInfo : 1|4@0+ (50.0,0.0) [0|0] "W/m2" Vector__XXX
 SG_ LightSensorStatus : 2|1@0+ (1.0,0.0) [0|0] "" Vector__XXX
 SG_ RightSolarLevelInfo : 7|5@0+ (50.0,0.0) [0|0] "W" Vector__XXX
 SG_ LeftSolarLevelInfo : 13|5@0+ (50.0,0.0) [0|0] "W" Vector__XXX

BO_ 1655 EMM_WakeUpFrame: 2 Vector__XXX
 SG_ EMM_WakeUp_Signal : 7|16@0+ (1.0,0.0) [0|0] "" Vector__XXX

BO_ 1580 EPS_CANHS_R_01: 1 Vector__XXX
 SG_ EPSCityModeActivationDisplay : 5|1@0+ (1.0,0.0) [0|0] "" Vector__XXX
 SG_ EPSWarning : 7|2@0+ (1.0,0.0) [0|0] "" Vector__XXX

BO_ 1890 EPS_to_DTOOL: 8 Vector__XXX
 SG_ EPS_to_DTOOL : 7|64@0+ (1.0,0.0) [0|0] "" Vector__XXX

BO_ 811 FCW_CANV_01: 5 Vector__XXX
 SG_ FCWWarning_Request : 6|2@0+ (1.0,0.0) [0|0] "" Vector__XXX
 SG_ FCWFailure_Status : 7|1@0+ (1.0,0.0) [0|0] "" Vector__XXX
 SG_ FCW_DistanceToObject : 15|12@0+ (0.05,0.0) [0|0] "m" Vector__XXX
 SG_ FCW_RelativeSpeed : 19|12@0- (0.05,-102.35) [0|0] "m/s" Vector__XXX
 SG_ FCW_NewObjectDetected : 34|1@0+ (1.0,0.0) [0|0] "" Vector__XXX
 SG_ FCW_MovingObjectStatus : 37|3@0+ (1.0,0.0) [0|0] "" Vector__XXX
 SG_ FCW_SystemStatus : 39|2@0+ (1.0,0.0) [0|0] "" Vector__XXX

BO_ 2013 FRONT_CAMERA_to_DTOOL: 8 Vector__XXX
 SG_ FRONT_CAMERA_to_DTOOL : 7|64@0+ (1.0,0.0) [0|0] "" Vector__XXX

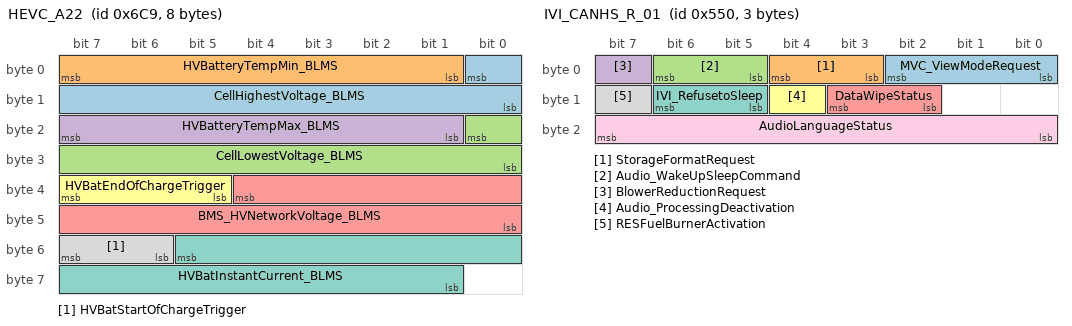
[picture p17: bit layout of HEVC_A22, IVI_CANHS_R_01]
BO_ 1737 HEVC_A22: 8 Vector__XXX
 SG_ CellHighestVoltage_BLMS : 0|9@0+ (0.01,1.0) [0|0] "V" Vector__XXX
 SG_ HVBatteryTempMin_BLMS : 7|7@0+ (1.0,0.0) [0|0] "" Vector__XXX
 SG_ CellLowestVoltage_BLMS : 16|9@0+ (0.01,1.0) [0|0] "V" Vector__XXX
 SG_ HVBatteryTempMax_BLMS : 23|7@0+ (1.0,0.0) [0|0] "" Vector__XXX
 SG_ BMS_HVNetworkVoltage_BLMS : 36|13@0+ (0.1,0.0) [0|0] "V" Vector__XXX
 SG_ HVBatEndOfChargeTrigger : 39|3@0+ (1.0,0.0) [0|0] "" Vector__XXX
 SG_ HVBatInstantCurrent_BLMS : 53|13@0+ (1.0,0.0) [0|0] "" Vector__XXX
 SG_ HVBatStartOfChargeTrigger : 55|2@0+ (1.0,0.0) [0|0] "" Vector__XXX

BO_ 1360 IVI_CANHS_R_01: 3 Vector__XXX
 SG_ MVC_ViewModeRequest : 2|3@0+ (1.0,0.0) [0|0] "" Vector__XXX
 SG_ StorageFormatRequest : 4|2@0+ (1.0,0.0) [0|0] "" Vector__XXX
 SG_ Audio_WakeUpSleepCommand : 6|2@0+ (1.0,0.0) [0|0] "" Vector__XXX
 SG_ BlowerReductionRequest : 7|1@0+ (1.0,0.0) [0|0] "" Vector__XXX
 SG_ DataWipeStatus : 11|2@0+ (1.0,0.0) [0|0] "" Vector__XXX
 SG_ Audio_ProcessingDeactivation : 12|1@0+ (1.0,0.0) [0|0] "" Vector__XXX
 SG_ IVI_RefusetoSleep : 14|2@0+ (1.0,0.0) [0|0] "" Vector__XXX
 SG_ RESFuelBurnerActivation : 15|1@0+ (1.0,0.0) [0|0] "" Vector__XXX
 SG_ AudioLanguageStatus : 23|8@0+ (1.0,0.0) [0|0] "" Vector__XXX

BO_ 1781 IVI_R10: 8 Vector__XXX
 SG_ ChargeCal5DurationChange_MMI : 7|11@0+ (1.0,0.0) [0|0] "min" Vector__XXX
 SG_ ChargeCal5BeginHourChange_MMI : 12|5@0+ (1.0,0.0) [0|0] "h" Vector__XXX
 SG_ ChargeCal5TuesdayChange_MMI : 16|1@0+ (1.0,0.0) [0|0] "" Vector__XXX
 SG_ ChargeCal5MondayChange_MMI : 17|1@0+ (1.0,0.0) [0|0] "" Vector__XXX
 SG_ ChargeCal5BeginMinChange_MMI : 23|6@0+ (1.0,0.0) [0|0] "min" Vector__XXX
 SG_ ChargeDelayedRequestValue : 26|11@0+ (1.0,1.0) [0|0] "min" Vector__XXX
 SG_ ChargeCal5SundayChange_MMI : 27|1@0+ (1.0,0.0) [0|0] "" Vector__XXX
 SG_ ChargeCal5SaturdayChange_MMI : 28|1@0+ (1.0,0.0) [0|0] "" Vector__XXX
 SG_ ChargeCal5FridayChange_MMI : 29|1@0+ (1.0,0.0) [0|0] "" Vector__XXX
 SG_ ChargeCal5ThursdayChange_MMI : 30|1@0+ (1.0,0.0) [0|0] "" Vector__XXX
 SG_ ChargeCal5WednesdayChange_MMI : 31|1@0+ (1.0,0.0) [0|0] "" Vector__XXX
 SG_ EcoTripResetRequest : 40|1@0+ (1.0,0.0) [0|0] "" Vector__XXX
 SG_ SC_UserElecPriceSetNbSlot : 45|5@0+ (1.0,0.0) [0|0] "" Vector__XXX
 SG_ ChargeDelayedRequest : 46|1@0+ (1.0,0.0) [0|0] "" Vector__XXX
 SG_ ChargeAlwaysRequest : 47|1@0+ (1.0,0.0) [0|0] "" Vector__XXX
 SG_ MVC_ViewModeRequest : 50|3@0+ (1.0,0.0) [0|0] "" Vector__XXX
 SG_ SC_UserElecPriceSetSlotDuration : 55|5@0+ (1.0,0.0) [0|0] "" Vector__XXX
 SG_ SC_UserElecPriceSetRelativeCost : 62|4@0+ (1.0,0.0) [0|0] "" Vector__XXX
 SG_ FuelSaveClearHistoRequest : 63|1@0+ (1.0,0.0) [0|0] "" Vector__XXX

BO_ 1782 IVI_R11: 7 Vector__XXX
 SG_ PreSoakCal1ArrivalHourChange_MMI : 1|5@0+ (1.0,0.0) [0|0] "h" Vector__XXX
 SG_ PreSoakCal1ArrivalMinChange_MMI : 7|6@0+ (1.0,0.0) [0|0] "min" Vector__XXX
 SG_ PreSoakCal1FridayChange_MMI : 8|1@0+ (1.0,0.0) [0|0] "" Vector__XXX
 SG_ PreSoakCal1ThursdayChange_MMI : 9|1@0+ (1.0,0.0) [0|0] "" Vector__XXX
 SG_ PreSoakCal1WednesdayChange_MMI : 10|1@0+ (1.0,0.0) [0|0] "" Vector__XXX
 SG_ PreSoakCal1TuesdayChange_MMI : 11|1@0+ (1.0,0.0) [0|0] "" Vector__XXX
 SG_ PreSoakCal1MondayChange_MMI : 12|1@0+ (1.0,0.0) [0|0] "" Vector__XXX
 SG_ PreSoakCal2ArrivalMinChange_MMI : 21|6@0+ (1.0,0.0) [0|0] "min" Vector__XXX
 SG_ PreSoakCal1SundayChange_MMI : 22|1@0+ (1.0,0.0) [0|0] "" Vector__XXX
 SG_ PreSoakCal1SaturdayChange_MMI : 23|1@0+ (1.0,0.0) [0|0] "" Vector__XXX
 SG_ PreSoakCal2WednesdayChange_MMI : 24|1@0+ (1.0,0.0) [0|0] "" Vector__XXX
 SG_ PreSoakCal2TuesdayChange_MMI : 25|1@0+ (1.0,0.0) [0|0] "" Vector__XXX
 SG_ PreSoakCal2MondayChange_MMI : 26|1@0+ (1.0,0.0) [0|0] "" Vector__XXX
 SG_ PreSoakCal2ArrivalHourChange_MMI : 31|5@0+ (1.0,0.0) [0|0] "h" Vector__XXX
 SG_ PreSoakCal3ArrivalMinChange_MMI : 35|6@0+ (1.0,0.0) [0|0] "min" Vector__XXX
 SG_ PreSoakCal2SundayChange_MMI : 36|1@0+ (1.0,0.0) [0|0] "" Vector__XXX
 SG_ PreSoakCal2SaturdayChange_MMI : 37|1@0+ (1.0,0.0) [0|0] "" Vector__XXX
 SG_ PreSoakCal2FridayChange_MMI : 38|1@0+ (1.0,0.0) [0|0] "" Vector__XXX
 SG_ PreSoakCal2ThursdayChange_MMI : 39|1@0+ (1.0,0.0) [0|0] "" Vector__XXX
 SG_ PreSoakCal3MondayChange_MMI : 40|1@0+ (1.0,0.0) [0|0] "" Vector__XXX
 SG_ PreSoakCal3ArrivalHourChange_MMI : 45|5@0+ (1.0,0.0) [0|0] "h" Vector__XXX
 SG_ PreSoakCalAllChange_MMI : 49|2@0+ (1.0,0.0) [0|0] "" Vector__XXX
 SG_ PreSoakCal3SundayChange_MMI : 50|1@0+ (1.0,0.0) [0|0] "" Vector__XXX
 SG_ PreSoakCal3SaturdayChange_MMI : 51|1@0+ (1.0,0.0) [0|0] "" Vector__XXX
 SG_ PreSoakCal3FridayChange_MMI : 52|1@0+ (1.0,0.0) [0|0] "" Vector__XXX
 SG_ PreSoakCal3ThursdayChange_MMI : 53|1@0+ (1.0,0.0) [0|0] "" Vector__XXX
 SG_ PreSoakCal3WednesdayChange_MMI : 54|1@0+ (1.0,0.0) [0|0] "" Vector__XXX
 SG_ PreSoakCal3TuesdayChange_MMI : 55|1@0+ (1.0,0.0) [0|0] "" Vector__XXX

BO_ 1783 IVI_R12: 7 Vector__XXX
 SG_ PreSoakCal4ArrivalHourChange_MMI : 1|5@0+ (1.0,0.0) [0|0] "h" Vector__XXX
 SG_ PreSoakCal4ArrivalMinChange_MMI : 7|6@0+ (1.0,0.0) [0|0] "min" Vector__XXX
 SG_ PreSoakCal4FridayChange_MMI : 8|1@0+ (1.0,0.0) [0|0] "" Vector__XXX
 SG_ PreSoakCal4ThursdayChange_MMI : 9|1@0+ (1.0,0.0) [0|0] "" Vector__XXX
 SG_ PreSoakCal4WednesdayChange_MMI : 10|1@0+ (1.0,0.0) [0|0] "" Vector__XXX
 SG_ PreSoakCal4TuesdayChange_MMI : 11|1@0+ (1.0,0.0) [0|0] "" Vector__XXX
 SG_ PreSoakCal4MondayChange_MMI : 12|1@0+ (1.0,0.0) [0|0] "" Vector__XXX
 SG_ PreSoakCal5ArrivalMinChange_MMI : 21|6@0+ (1.0,0.0) [0|0] "min" Vector__XXX
 SG_ PreSoakCal4SundayChange_MMI : 22|1@0+ (1.0,0.0) [0|0] "" Vector__XXX
 SG_ PreSoakCal4SaturdayChange_MMI : 23|1@0+ (1.0,0.0) [0|0] "" Vector__XXX
 SG_ PreSoakCal5WednesdayChange_MMI : 24|1@0+ (1.0,0.0) [0|0] "" Vector__XXX
 SG_ PreSoakCal5TuesdayChange_MMI : 25|1@0+ (1.0,0.0) [0|0] "" Vector__XXX
 SG_ PreSoakCal5MondayChange_MMI : 26|1@0+ (1.0,0.0) [0|0] "" Vector__XXX
 SG_ PreSoakCal5ArrivalHourChange_MMI : 31|5@0+ (1.0,0.0) [0|0] "h" Vector__XXX
 SG_ GainECOdistanceDisplay : 35|13@0+ (1.0,0.0) [0|0] "" Vector__XXX
 SG_ PreSoakCal5SundayChange_MMI : 36|1@0+ (1.0,0.0) [0|0] "" Vector__XXX
 SG_ PreSoakCal5SaturdayChange_MMI : 37|1@0+ (1.0,0.0) [0|0] "" Vector__XXX
 SG_ PreSoakCal5FridayChange_MMI : 38|1@0+ (1.0,0.0) [0|0] "" Vector__XXX
 SG_ PreSoakCal5ThursdayChange_MMI : 39|1@0+ (1.0,0.0) [0|0] "" Vector__XXX

BO_ 1779 IVI_R8: 8 Vector__XXX
 SG_ ChargeCal1DurationChange_MMI : 7|11@0+ (1.0,0.0) [0|0] "min" Vector__XXX
 SG_ ChargeCal1BeginHourChange_MMI : 12|5@0+ (1.0,0.0) [0|0] "h" Vector__XXX
 SG_ ChargeCal1TuesdayChange_MMI : 16|1@0+ (1.0,0.0) [0|0] "" Vector__XXX
 SG_ ChargeCal1MondayChange_MMI : 17|1@0+ (1.0,0.0) [0|0] "" Vector__XXX
 SG_ ChargeCal1BeginMinChange_MMI : 23|6@0+ (1.0,0.0) [0|0] "min" Vector__XXX
 SG_ ChargeCal1SundayChange_MMI : 27|1@0+ (1.0,0.0) [0|0] "" Vector__XXX
 SG_ ChargeCal1SaturdayChange_MMI : 28|1@0+ (1.0,0.0) [0|0] "" Vector__XXX
 SG_ ChargeCal1FridayChange_MMI : 29|1@0+ (1.0,0.0) [0|0] "" Vector__XXX
 SG_ ChargeCal1ThursdayChange_MMI : 30|1@0+ (1.0,0.0) [0|0] "" Vector__XXX
 SG_ ChargeCal1WednesdayChange_MMI : 31|1@0+ (1.0,0.0) [0|0] "" Vector__XXX
 SG_ ChargeCal2DurationChange_MMI : 39|11@0+ (1.0,0.0) [0|0] "min" Vector__XXX
 SG_ ChargeCal2BeginHourChange_MMI : 44|5@0+ (1.0,0.0) [0|0] "h" Vector__XXX
 SG_ ChargeCal2TuesdayChange_MMI : 48|1@0+ (1.0,0.0) [0|0] "" Vector__XXX
 SG_ ChargeCal2MondayChange_MMI : 49|1@0+ (1.0,0.0) [0|0] "" Vector__XXX
 SG_ ChargeCal2BeginMinChange_MMI : 55|6@0+ (1.0,0.0) [0|0] "min" Vector__XXX
 SG_ ChargeCalAllChange_MMI : 58|2@0+ (1.0,0.0) [0|0] "" Vector__XXX
 SG_ ChargeCal2SundayChange_MMI : 59|1@0+ (1.0,0.0) [0|0] "" Vector__XXX
 SG_ ChargeCal2SaturdayChange_MMI : 60|1@0+ (1.0,0.0) [0|0] "" Vector__XXX
 SG_ ChargeCal2FridayChange_MMI : 61|1@0+ (1.0,0.0) [0|0] "" Vector__XXX
 SG_ ChargeCal2ThursdayChange_MMI : 62|1@0+ (1.0,0.0) [0|0] "" Vector__XXX
 SG_ ChargeCal2WednesdayChange_MMI : 63|1@0+ (1.0,0.0) [0|0] "" Vector__XXX

BO_ 1780 IVI_R9: 8 Vector__XXX
 SG_ ChargeCal3DurationChange_MMI : 7|11@0+ (1.0,0.0) [0|0] "min" Vector__XXX
 SG_ ChargeCal3BeginHourChange_MMI : 12|5@0+ (1.0,0.0) [0|0] "h" Vector__XXX
 SG_ ChargeCal3TuesdayChange_MMI : 16|1@0+ (1.0,0.0) [0|0] "" Vector__XXX
 SG_ ChargeCal3MondayChange_MMI : 17|1@0+ (1.0,0.0) [0|0] "" Vector__XXX
 SG_ ChargeCal3BeginMinChange_MMI : 23|6@0+ (1.0,0.0) [0|0] "min" Vector__XXX
 SG_ ChargeCal3SundayChange_MMI : 27|1@0+ (1.0,0.0) [0|0] "" Vector__XXX
 SG_ ChargeCal3SaturdayChange_MMI : 28|1@0+ (1.0,0.0) [0|0] "" Vector__XXX
 SG_ ChargeCal3FridayChange_MMI : 29|1@0+ (1.0,0.0) [0|0] "" Vector__XXX
 SG_ ChargeCal3ThursdayChange_MMI : 30|1@0+ (1.0,0.0) [0|0] "" Vector__XXX
 SG_ ChargeCal3WednesdayChange_MMI : 31|1@0+ (1.0,0.0) [0|0] "" Vector__XXX
 SG_ ChargeCal4DurationChange_MMI : 39|11@0+ (1.0,0.0) [0|0] "min" Vector__XXX
 SG_ ChargeCal4BeginHourChange_MMI : 44|5@0+ (1.0,0.0) [0|0] "h" Vector__XXX
 SG_ ChargeCal4TuesdayChange_MMI : 48|1@0+ (1.0,0.0) [0|0] "" Vector__XXX
 SG_ ChargeCal4MondayChange_MMI : 49|1@0+ (1.0,0.0) [0|0] "" Vector__XXX
 SG_ ChargeCal4BeginMinChange_MMI : 55|6@0+ (1.0,0.0) [0|0] "min" Vector__XXX
 SG_ ChargeCal4SundayChange_MMI : 59|1@0+ (1.0,0.0) [0|0] "" Vector__XXX
 SG_ ChargeCal4SaturdayChange_MMI : 60|1@0+ (1.0,0.0) [0|0] "" Vector__XXX
 SG_ ChargeCal4FridayChange_MMI : 61|1@0+ (1.0,0.0) [0|0] "" Vector__XXX
 SG_ ChargeCal4ThursdayChange_MMI : 62|1@0+ (1.0,0.0) [0|0] "" Vector__XXX
 SG_ ChargeCal4WednesdayChange_MMI : 63|1@0+ (1.0,0.0) [0|0] "" Vector__XXX

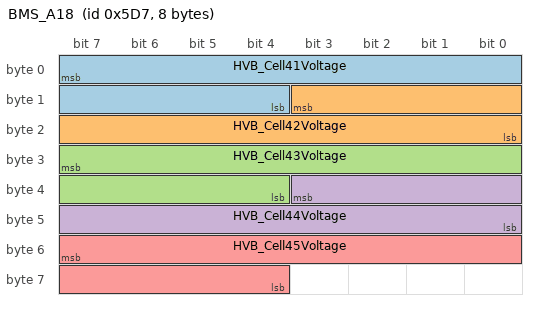
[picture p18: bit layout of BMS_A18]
BO_ 1495 BMS_A18: 8 Vector__XXX // Original Name: VehicleID_CANHS_R_01
 SG_ HVB_Cell41Voltage : 7|12@0+ (0.001,2.0) [0|0] "V" Vector__XXX // Original Name: VehicleID
 SG_ HVB_Cell42Voltage : 11|12@0+ (0.001,2.0) [0|0] "V" Vector__XXX // Original Name: VehicleID
 SG_ HVB_Cell43Voltage : 31|12@0+ (0.001,2.0) [0|0] "V" Vector__XXX // Original Name: VehicleID
 SG_ HVB_Cell44Voltage : 35|12@0+ (0.001,2.0) [0|0] "V" Vector__XXX // Original Name: VehicleID
 SG_ HVB_Cell45Voltage : 55|12@0+ (0.001,2.0) [0|0] "V" Vector__XXX // Original Name: VehicleID

VAL_ 1039 SelectedDistanceDisplayRequest 0 "Fixed value transmitted" ;
VAL_ 1039 DistanceOverrideDisplayRequest 0 "Fixed value transmitted" ;
VAL_ 1039 SpeedOverrideDisplayRequest 0 "Fixed value transmitted" ;
VAL_ 1039 ACCLSF_StatusDisplay 3 "Fixed value transmitted" ;
VAL_ 1039 DriverTakeOverDisplayRequest 0 "Fixed value transmitted" ;
VAL_ 1039 AEBS_FailureDisplayRequest 0 "No AEBS failure display requested " 1 "AEBS failure display requested " ;
VAL_ 1039 AEBS_DangerAlert 0 "No AEBS Danger Alert requested " 1 "AEBS Danger Alert requested" ;
VAL_ 1039 DetectedTargetDisplayRequest_TM 0 "Fixed value transmitted" ;
VAL_ 1039 DW_ActivationState_TM 0 "Fixed value transmitted" ;
VAL_ 1039 AEBS_DistanceWarning 0 "No Distance Warning alert" 1 "Distance Warning alert" ;
VAL_ 1039 AEBS_TemporarlyFailureDisplay 0 "Fixed value transmitted" ;
VAL_ 1039 AEBS_PedestrianAlert 0 "Fixed value transmitted" ;
VAL_ 1039 SpeedNotRelevantDisplayRequest 0 "Fixed value transmitted" ;
VAL_ 1039 FollowUpTimeBlinkRequest_TM 0 "Fixed value transmitted" ;
VAL_ 1039 FCW_ActivationState 0 "FCW NOT Activated" 1 "FCW Activated" ;
VAL_ 444 ForceRequestConfirmed 0 "Fixed value transmitted" ;
VAL_ 444 ACCStatus 0 "Fixed value transmitted" ;
VAL_ 444 HydraulicPreFillRequest 0 "Prefill NOT Requested" 1 "Prefill Requested" ;
VAL_ 444 HBAThresholdRequest 0 "HBA standard threshold" 1 "HBA low threshold" ;
VAL_ 444 BrakeTorqueGainFlag_AEBS 0 "Reserved for Safety" 1 "Brake Gain Off" 2 "Brake Gain ON" 3 "Unavailable Value" ;
VAL_ 444 AEBS_FailureStatus 0 "No AEBS failure. AEBS available" 1 "AEBS failure. AEBS not available" ;
VAL_ 444 BrakeTorqueOrder 5 "No Brake Request" 6 "Brake Torque Request ACC " 9 "Brake Moderate Torque Request AEBS" 10 "Brake Strong Torque Request AEBS" 12 "Brake City Torque Request AEBS" 13 "Brake Maximum Torque Request AEBS" 15 "Unavailable" ;
VAL_ 1619 Crash_DetectionOutOfOrder 0 "no Crash Detection Out Of Order" 1 "Crash Detection Out Of Order" ;
VAL_ 1619 CrashDetected 0 "no crash detected" 1 "crash detected" ;
VAL_ 1619 SecondRowCenterSafetyBeltState 3 "Fixed value transmitted" ;
VAL_ 1619 AIRBAGMalfunction 0 "no AIRBAG system malfunction" 1 "AIRBAG system malfunction" ;
VAL_ 1619 PassengerAIRBAG_Inhibition 0 "Passenger AIRBAG not inhibited" 1 "Passenger AIRBAG inhibited" ;
VAL_ 1619 FrontPassengerSafetyBeltReminder 0 "Passenger safety belt reminder : no warning" 1 "Passenger safety belt reminder Warning level 1" 2 "Passenger safety belt reminder Warning level 2" 3 "Not Used" ;
VAL_ 1619 DriverSafetyBeltReminder 0 "Driver safety belt reminder : No Warning" 1 "Driver safety belt reminder Warning level 1" 2 "Driver safety belt reminder  Warning level 2" 3 "Driver seatbelt is buckled (Level 3 - EDISON)" ;
VAL_ 1619 ThirdRowLeftSafetyBeltState 0 "Fixed value transmitted" ;
VAL_ 1619 EDRActiveDisplayRequest 0 "Fixed value transmitted" ;
VAL_ 1619 ValidAIRBAGInformation 0 "no valid AIRBAG Information" 1 "Valid AIRBAG Information" ;
VAL_ 1619 SecondRowRightSafetyBeltState 0 "Right SB not monitored" 1 "Right SB unfastened" 2 "Right SB fastened" 3 "Unavailable" ;
VAL_ 1619 SecondRowLeftSafetyBeltState 0 "Left SB not monitored" 1 "Left SB unfastened" 2 "Left SB fastened" 3 "Unavailable" ;
VAL_ 1619 ROPS_Position 0 "Fixed value transmitted" ;
VAL_ 1619 PassAirbagONDisplayReq 0 "Fixed value transmitted" ;
VAL_ 1619 ThirdRowRightSafetyBeltState 0 "Fixed value transmitted" ;
VAL_ 1623 HeatingFanActivationStatus 0 "Fixed value transmitted" ;
VAL_ 1623 PreHeatingStart 0 "Fixed value transmitted" ;
VAL_ 1623 ACCSupplyState 0 "Fixed value transmitted" ;
VAL_ 1623 IKeyCardDetectionStatus 0 "Fixed value transmitted" ;
VAL_ 1623 TechnicalWakeUpType 0 "Fixed value transmitted" ;
VAL_ 848 VehicleStateExtented 0 "Sleeping " 1 "Technical Wakeup" 2 "CutOffPending" 3 "BatTempoLevel" 4 "AccessoryLevel" 5 "IgnitionLevel" 6 "StartingInProgress" 7 "EngineRunning" 8 "AutoStart" 9 "EngineSystemStop" 15 "UnvailableValue" ;
VAL_ 848 StartAutoSystemFailure 0 "Fixed value transmitted" ;
VAL_ 848 BCM_WakeUpSleepCommand 0 "Go to Sleep" 1 "reserved" 2 "reserved_2" 3 "WakeUp" ;
VAL_ 848 LightsRequest 0 "Fixed value transmitted" ;
VAL_ 848 TailGateButtonPushed 0 "Unvailable Value" 1 "No TailGate Button is Pushed" 2 "TailGate Button is Pushed" 3 "Not Used" ;
VAL_ 848 FlashingIndicatorCommandPosition 0 "No direction indicator request" 1 "Left Flashing Indicators command ON" 2 "Right Flashing Indicators command ON" 3 "Not used" ;
VAL_ 848 GenericApplicativeDiagEnable 0 "Only faults reports and alerts that MUST remain active during cranking or sleeping periods are enabled" 1 "All  faults reports and alerts not related to APC power level are enabled" 2 "All  faults reports and alerts are enabled" 3 "Unavailable" ;
VAL_ 848 BrakeInfoStatus 1 "Brake pedal not pressed" 2 "Brake pedal pressed" 4 "Brake pedal confirmed pressed" 7 "unavailable" ;
VAL_ 848 DiagMuxOn_BCM 0 "counting and storage of CAN mute/absent failures  masked" 1 "counting and storage of CAN mute/absent failures not masked" ;
VAL_ 848 NeutralSwitchFaultDisplay 0 "No neutral switch failure display request" 1 "Neutral switch failure display requested" ;
VAL_ 848 VehicleOutsideLockedState 0 "Vehicle not locked from the outside by the customer" 1 "Vehicle Locked from the outside by the customer" ;
VAL_ 848 PassengerDoorState 0 "Unvailable Value" 1 "Passenger door closed" 2 "Passenger door open" 3 "Not used" ;
VAL_ 848 DriverDoorState 0 "Unvailable Value" 1 "Driver door closed" 2 "Driver door open" 3 "Not Used" ;
VAL_ 848 EngineHoodState 0 "Unvailable value" 1 "Hood opened" 2 "Hood closed" 3 "Not used" ;
VAL_ 848 WarningLightsStatus 0 "Fixed value transmitted" ;
VAL_ 848 WakeUpType 0 "Customer wake up" 1 "Technical wake up" ;
VAL_ 848 EcoModeRequest 0 "Unavailable" 1 "Eco mode requested" 2 "Eco mode not requested" 3 "Not used" ;
VAL_ 1373 Blower_StateBCM 0 "Blower fan OFF" 1 "Blower fan ON" ;
VAL_ 1373 BrakeSwitchFailure 3 "Fixed value transmitted" ;
VAL_ 1373 FrontWashingRequest 0 "Unvailable Value" 1 "No Washing Requested" 2 "Washing Requested" 3 "Not Used" ;
VAL_ 1373 NeutralContact 0 "not used" 1 "neutral contact not reached" 2 "neutral contact reached" 3 "unavailable" ;
VAL_ 1373 RearGearEngaged 0 "Not used" 1 "Rear Gear not Engaged" 2 "Rear Gear Engaged" 3 "unavailable" ;
VAL_ 1373 KeyVehicle 0 "Keyless vehicle" 1 "Unavailable" 2 "Not used" 3 "Key vehicle" ;
VAL_ 1373 PTC_Thermal_Regulator_Freeze 0 "No PTC thermal Regulator Freeze requested" 1 "PTC thermal Regulator Freeze requested" ;
VAL_ 1373 PTCEngineIdleSpeedRequest 0 "No PTC engine Idle speed increase request" 1 "PTC engine Idle speed increase request" ;
VAL_ 1373 DischargedBatTempoRequest 1 "Fixed value transmitted" ;
VAL_ 1373 RearDefrostEngaged 0 "Rear Defrost not engaged" 1 "Rear Defrost engaged" ;
VAL_ 1373 ClutchSwitchMinimumTravel 0 "Not used" 1 "Clutch pedal not pressed                               " 2 "Clutch pedal pressed at minimum" 3 "Unavailable" ;
VAL_ 1373 ClutchSwitchMaximumTravel 0 "Not used" 1 "Clutch pedal not pressed at maximum                             " 2 "Clutch pedal pressed at maximum" 3 "Unavailable" ;
VAL_ 1373 StarterStatus 0 "cranking relay switched off" 1 "short relaxation active" 2 "long relaxation active" 3 "cranking relay switched on" ;
VAL_ 1373 ParkingBrakeStatus 3 "Fixed value transmitted" ;
VAL_ 1373 PTCState 0 "Fixed value transmitted" ;
VAL_ 1373 AutoStartFailure 0 "Fixed value transmitted" ;
VAL_ 1373 StarterInhibtion 0 "Fixed value transmitted" ;
VAL_ 1373 DeliveryModeInformation_v2 0 "customer mode" 1 "delivery mode level 1" 2 "delivery mode level 2" 3 "Not used" ;
VAL_ 1373 FuelBurnerActivationState 1 "Fixed value transmitted" ;
VAL_ 1373 BCM_SailingIdleForbidden 1 "Fixed value transmitted" ;
VAL_ 1373 HighBeamState 0 "High beam not activated" 1 "High beam activated" ;
VAL_ 1373 LowBeamState 0 "Low beam not activated" 1 "Low beam activated" ;
VAL_ 1373 DisplayRequest 0 "Display activation not requested" 1 "Display activation requested" ;
VAL_ 1373 ClimateCoolingRequest 0 "no air conditionning requested" 1 "air conditionning requested" ;
VAL_ 1373 UserIdentification 0 "Unavailable" 1 "User n°1" 2 "User n°2" 3 "User n°3" 4 "User n°4" ;
VAL_ 1373 DayNightStatusSynth 0 "Day" 1 "Night" ;
VAL_ 1373 InternalLightingActivationState 0 "Fixed value transmitted" ;
VAL_ 1373 DeliveryModeInformation 0 "customer mode" 1 "delivery mode" ;
VAL_ 1373 DriverDoorLockedStatus 0 "Driver Door Unlocked" 1 "Driver Door Locked" ;
VAL_ 1373 RKEButtonPressed 0 "No Request" 1 "Lock button Pressed " 2 "Long Lock button Pressed " 3 "Unlock button Pressed " 4 "Long Unlock button Pressed " 5 "button 3 Pressed " 6 "Long button 3 Pressed " 7 "button 4 Pressed " 8 "Long button 4 Pressed " 9 "Not Used" 10 "Not Used_10" 11 "Not Used_11" 12 "Not Used_12" 13 "Not Used_13" 14 "Not Used_14" 15 "Unavailable" ;
VAL_ 1373 FrontDefrostEngaged 0 "Fixed value transmitted" ;
VAL_ 1373 StartingRequest_EV 0 "Unavailable" 1 "Starting requested" 2 "Starting not requested" 3 "Safety Reserved" ;
VAL_ 1196 GearboxChangeOnCrankingRequest 0 "No gearbox lever change requested " 1 "Gearbox P position requested" 2 "Gearbox N position requested" 3 "unavailable value" ;
VAL_ 1196 Reserved_1bit 0 "Fixed value transmitted" ;
VAL_ 1196 DirectionSideConfirmation 0 "Left-hand drive" 1 "Right-hand drive" ;
VAL_ 1196 VehicleActivationState 1 "Fixed value transmitted" ;
VAL_ 1196 CustomerAutoStartWill 0 "Fixed value transmitted" ;
VAL_ 1196 BCM_StopAutoForbidden 0 "Unavailable" 1 "Auto Stop forbidden" 2 "Auto stop authorized" 3 "Not used" ;
VAL_ 1196 DriverDoorStatusSupposedFailure 0 "no supposed Driver's door failure" 1 "supposed driver's door failure" ;
VAL_ 1196 BattWarnReq_Level_Lo_BCM 0 "No Battery Warning Level-Lo requested" 1 "Battery Warning Level-Lo requested" ;
VAL_ 1196 BattWarnReq_Level_Hi_BCM 0 "No Battery Warning Level-Hi requested" 1 "Battery Warning Level-Hi requested" ;
VAL_ 1196 Battery14VCSensorFailureStatus 0 "No Sensor Failure" 1 "Sensor Failure" ;
VAL_ 1196 StopStartSwitch 0 "Unavailable" 1 "Switch Pressed" 2 "Switch Released" 3 "Not Used" ;
VAL_ 1196 BatterySetPointGeneratorStatus 0 "nominal mode" 1 "default detected" 2 "default confirmed" 3 "battery disconnected" ;
VAL_ 1196 TailGateStatusSupposedFailure 0 "no supposed TailGate's door failure" 1 "supposed TailGate's door failure" ;
VAL_ 1196 AuthorizationPH 0 "Fixed value transmitted" ;
VAL_ 1196 EEM_SailingIdleForbidden 1 "Fixed value transmitted" ;
VAL_ 1196 IgnitionSupplyConfirmation_BCM 0 "no primary ignition supply" 1 "primary ignition supply on" ;
VAL_ 1196 IdleSpeedInhibitionRequest_BCM 0 "Unavalaible Value" 1 "IdleSpeed Inhibition Requested" 2 "IdleSpeed Inhibition not Requested" 3 "Not Used" ;
VAL_ 1196 HornRequest 0 "No Request" 1 "Horn OFF Request" 2 "Panic Horn Request" 3 "Lock Horn Request" 4 "Not used" 5 "Perimetric Alarm Horn Request" 6 "Silent Mode Deactivation Horn Request" 7 "Unavailable" ;
VAL_ 1196 RemoteLight_BCM 0 "No request" 1 "Remote lighting request" ;
VAL_ 1196 WindowsLiftAuthorization 0 "Unavailable" 1 "Window Lift not authorized" 2 "Window Lift authorized" 3 "Not Used" ;
VAL_ 432 GenMode 0 "GENMODE0 Llimitation requested by Engine" 1 "GENMODE1 Nominal strategy Mode" 2 "GENMODE2 ESM intermediate Mode" 3 "GENMODE3 Battery protection" 4 "GENMODE4 ESM Dischage Mode" 5 "GENMODE5 ESM Regeneration Mode" 6 "GENMODE6 ESM inhibited by wiper" 7 "GENMODE7 ESM inhibited by actuator" 8 "GENMODE8 Maximum Voltage by endurance" 9 "GENMODE9 MinimumVoltageByECM" 10 "GENMODE10 Floating Mode" 11 "Not Used" 12 "Not Used_12" 13 "Not Used_13" 14 "Not Used_14" 15 "Unavailable" ;
VAL_ 1700 ChargeCal1Tuesday 0 "Unselected day" 1 "Selected day" ;
VAL_ 1700 ChargeCal1Monday 0 "Unselected day" 1 "Selected day" ;
VAL_ 1700 ZEnSwitchState 1 "Fixed value transmitted" ;
VAL_ 1700 ChargeCal1Sunday 0 "Unselected day" 1 "Selected day" ;
VAL_ 1700 ChargeCal1Saturday 0 "Unselected day" 1 "Selected day" ;
VAL_ 1700 ChargeCal1Friday 0 "Unselected day" 1 "Selected day" ;
VAL_ 1700 ChargeCal1Thursday 0 "Unselected day" 1 "Selected day" ;
VAL_ 1700 ChargeCal1Wednesday 0 "Unselected day" 1 "Selected day" ;
VAL_ 1700 ChargeCal2Tuesday 0 "Unselected day" 1 "Selected day" ;
VAL_ 1700 ChargeCal2Monday 0 "Unselected day" 1 "Selected day" ;
VAL_ 1700 ChargeCal2Sunday 0 "Unselected day" 1 "Selected day" ;
VAL_ 1700 ChargeCal2Saturday 0 "Unselected day" 1 "Selected day" ;
VAL_ 1700 ChargeCal2Friday 0 "Unselected day" 1 "Selected day" ;
VAL_ 1700 ChargeCal2Thursday 0 "Unselected day" 1 "Selected day" ;
VAL_ 1700 ChargeCal2Wednesday 0 "Unselected day" 1 "Selected day" ;
VAL_ 1702 ChargeCal3Tuesday 0 "Unselected day" 1 "Selected day" ;
VAL_ 1702 ChargeCal3Monday 0 "Unselected day" 1 "Selected day" ;
VAL_ 1702 ChargeCal3Sunday 0 "Unselected day" 1 "Selected day" ;
VAL_ 1702 ChargeCal3Saturday 0 "Unselected day" 1 "Selected day" ;
VAL_ 1702 ChargeCal3Friday 0 "Unselected day" 1 "Selected day" ;
VAL_ 1702 ChargeCal3Thursday 0 "Unselected day" 1 "Selected day" ;
VAL_ 1702 ChargeCal3Wednesday 0 "Unselected day" 1 "Selected day" ;
VAL_ 1702 ChargeCal4Tuesday 0 "Unselected day" 1 "Selected day" ;
VAL_ 1702 ChargeCal4Monday 0 "Unselected day" 1 "Selected day" ;
VAL_ 1702 ChargeCal4Sunday 0 "Unselected day" 1 "Selected day" ;
VAL_ 1702 ChargeCal4Saturday 0 "Unselected day" 1 "Selected day" ;
VAL_ 1702 ChargeCal4Friday 0 "Unselected day" 1 "Selected day" ;
VAL_ 1702 ChargeCal4Thursday 0 "Unselected day" 1 "Selected day" ;
VAL_ 1702 ChargeCal4Wednesday 0 "Unselected day" 1 "Selected day" ;
VAL_ 1703 ChargeCal5Tuesday 0 "Unselected day" 1 "Selected day" ;
VAL_ 1703 ChargeCal5Monday 0 "Unselected day" 1 "Selected day" ;
VAL_ 1703 ChargeCal5Sunday 0 "Unselected day" 1 "Selected day" ;
VAL_ 1703 ChargeCal5Saturday 0 "Unselected day" 1 "Selected day" ;
VAL_ 1703 ChargeCal5Friday 0 "Unselected day" 1 "Selected day" ;
VAL_ 1703 ChargeCal5Thursday 0 "Unselected day" 1 "Selected day" ;
VAL_ 1703 ChargeCal5Wednesday 0 "Unselected day" 1 "Selected day" ;
VAL_ 1703 UnlockChargeInletRequest 0 "Fixed value transmitted" ;
VAL_ 1703 ChargeAuthorization_BCM_v2 0 "Fixed value transmitted" ;
VAL_ 1703 ProgrammedChargeStatus 0 "Always authorized charge" 1 "Delayed charge" 2 "Programmed charge by Calendar" 3 "Not Used" ;
VAL_ 1703 ChargeAuthorization_BCM 0 "Fixed value transmitted" ;
VAL_ 1705 PreSoakCal1Friday 0 "Unselected day" 1 "Selected day" ;
VAL_ 1705 PreSoakCal1Thursday 0 "Unselected day" 1 "Selected day" ;
VAL_ 1705 PreSoakCal1Wednesday 0 "Unselected day" 1 "Selected day" ;
VAL_ 1705 PreSoakCal1Tuesday 0 "Unselected day" 1 "Selected day" ;
VAL_ 1705 PreSoakCal1Monday 0 "Unselected day" 1 "Selected day" ;
VAL_ 1705 PreSoakCal1Sunday 0 "Unselected day" 1 "Selected day" ;
VAL_ 1705 PreSoakCal1Saturday 0 "Unselected day" 1 "Selected day" ;
VAL_ 1705 PreSoakCal2Wednesday 0 "Unselected day" 1 "Selected day" ;
VAL_ 1705 PreSoakCal2Tuesday 0 "Unselected day" 1 "Selected day" ;
VAL_ 1705 PreSoakCal2Monday 0 "Unselected day" 1 "Selected day" ;
VAL_ 1705 PreSoakCal2Sunday 0 "Unselected day" 1 "Selected day" ;
VAL_ 1705 PreSoakCal2Saturday 0 "Unselected day" 1 "Selected day" ;
VAL_ 1705 PreSoakCal2Friday 0 "Unselected day" 1 "Selected day" ;
VAL_ 1705 PreSoakCal2Thursday 0 "Unselected day" 1 "Selected day" ;
VAL_ 1705 PreSoakCal3Monday 0 "Unselected day" 1 "Selected day" ;
VAL_ 1705 PreSoakCal3Sunday 0 "Unselected day" 1 "Selected day" ;
VAL_ 1705 PreSoakCal3Saturday 0 "Unselected day" 1 "Selected day" ;
VAL_ 1705 PreSoakCal3Friday 0 "Unselected day" 1 "Selected day" ;
VAL_ 1705 PreSoakCal3Thursday 0 "Unselected day" 1 "Selected day" ;
VAL_ 1705 PreSoakCal3Wednesday 0 "Unselected day" 1 "Selected day" ;
VAL_ 1705 PreSoakCal3Tuesday 0 "Unselected day" 1 "Selected day" ;
VAL_ 1706 PreSoakCal4Friday 0 "Unselected day" 1 "Selected day" ;
VAL_ 1706 PreSoakCal4Thursday 0 "Unselected day" 1 "Selected day" ;
VAL_ 1706 PreSoakCal4Wednesday 0 "Unselected day" 1 "Selected day" ;
VAL_ 1706 PreSoakCal4Tuesday 0 "Unselected day" 1 "Selected day" ;
VAL_ 1706 PreSoakCal4Monday 0 "Unselected day" 1 "Selected day" ;
VAL_ 1706 PreSoakCal4Sunday 0 "Unselected day" 1 "Selected day" ;
VAL_ 1706 PreSoakCal4Saturday 0 "Unselected day" 1 "Selected day" ;
VAL_ 1706 PreSoakCal5Wednesday 0 "Unselected day" 1 "Selected day" ;
VAL_ 1706 PreSoakCal5Tuesday 0 "Unselected day" 1 "Selected day" ;
VAL_ 1706 PreSoakCal5Monday 0 "Unselected day" 1 "Selected day" ;
VAL_ 1706 PreSoakCal5Sunday 0 "Unselected day" 1 "Selected day" ;
VAL_ 1706 PreSoakCal5Saturday 0 "Unselected day" 1 "Selected day" ;
VAL_ 1706 PreSoakCal5Friday 0 "Unselected day" 1 "Selected day" ;
VAL_ 1706 PreSoakCal5Thursday 0 "Unselected day" 1 "Selected day" ;
VAL_ 578 MSRinRegulation 0 "no MSR regulation" 1 "MSR in regulation" ;
VAL_ 578 AYCMalfunction 0 "no AYC malfunction" 1 "AYC malfunction" ;
VAL_ 578 AYCinRegulation 0 "no AYC regulation" 1 "AYC in regulation" ;
VAL_ 578 HSAMalfunction 0 "no HSA malfunction" 1 "HSA malfunction" ;
VAL_ 578 ASRMalfunction 0 "No ASR malfunction" 1 "ASR malfunction" ;
VAL_ 578 ASRinRegulation 0 "no ASR regulation" 1 "ASR in regulation" ;
VAL_ 578 ABSMalfunction 0 "no ABS malfunction" 1 "ABS malfunction" ;
VAL_ 578 ABSinRegulation 0 "no ABS regulation" 1 "ABS in regulation" ;
VAL_ 578 ESP_TorqueControlType 0 "no torque request" 5 "ASR torque request (decrease torque request)" 6 "MSR torque request (increase torque request)" ;
VAL_ 578 MSRMalfunction 0 "no MSR malfunction" 1 "MSR malfunction" ;
VAL_ 578 HSA_ActivationState 0 "Unavailable" 1 "HSA  not activated" 2 "HSA  activated" 3 "not Used" ;
VAL_ 578 ShiftingAuthorization 0 "gear shift forbidden" 1 "shift down authorized" 2 "shift up authorized" 3 "shift up or down authorized" ;
VAL_ 302 MuSplit_Clock 0 "Fixed value transmitted" ;
VAL_ 302 ESP_RWARequestType 0 "Fixed value transmitted" ;
VAL_ 1495 HDC_StatusDisplay 0 "Fixed value transmitted" ;
VAL_ 1495 WheelsLockingState 0 "Fixed value transmitted" ;
VAL_ 1495 HDC_TakeoverAlert 0 "Fixed value transmitted" ;
VAL_ 1495 VehicleSpeedSign 3 "Fixed value transmitted" ;
VAL_ 1495 SideWindAssistActivationDispReq 0 "No display" 1 "Display Request" ;
VAL_ 1495 HDC_ButtonStatus 0 "Fixed value transmitted" ;
VAL_ 1495 HDC_ActivationRefusedDisplay 0 "Fixed value transmitted" ;
VAL_ 850 BrakeVacuumStatus 0 "Sensor or Sensorless Strategy Unavailable" 1 "Vacuum level above minimum level" 2 "Vacuum level below minimum level" 3 "Unavailable" ;
VAL_ 850 DriverBrake 3 "Fixed value transmitted" ;
VAL_ 850 ESP_StopLampRequest 0 "Reserved" 1 "Stops lamps off request" 2 "Stop lamps on request" 3 "Reserved_3" ;
VAL_ 850 ABS_WarningRequest 0 "reserved" 1 "warning lamps off request" 2 "warning lamps on request" 3 "reserved_3" ;
VAL_ 850 Idle_Stop_Brake_Hold_Function_Standby 1 "Fixed value transmitted" ;
VAL_ 850 FHSA_PABHolding 0 "Fixed value transmitted" ;
VAL_ 850 FHSA_PABStatus 0 "Fixed value transmitted" ;
VAL_ 850 ACC_SDL_StatusControl 0 "Fixed value transmitted" ;
VAL_ 850 ACC_SDL_BrakeRequestStatus 0 "Fixed value transmitted" ;
VAL_ 850 ACC_SDL_BrakeAcknowledgment 0 "Fixed value transmitted" ;
VAL_ 850 NoBrakeForce 0 "Fixed value transmitted" ;
VAL_ 695 ActiveBoosterStatus 0 "Fixed value transmitted" ;
VAL_ 695 ACCBrakeRequestsConsistent 0 "Fixed value transmitted" ;
VAL_ 695 ACCBrakeLeadtimeControl 0 "Fixed value transmitted" ;
VAL_ 695 ACCBrakingPerformanceStatus 0 "Unavailable" 1 "Not used" 2 "Impossible to execute request" 3 "Not used_3" 4 "Not used_4" 5 "ACC Braking Fully Operational" 6 "Not used_6" 7 "Not used_7" ;
VAL_ 695 AccelMonitoringStatus 0 "Fixed value transmitted" ;
VAL_ 695 DriverBrakingStatus 7 "Fixed value transmitted" ;
VAL_ 695 NonDrivingWheelsStuckDetectionFlag 0 "Unavailable" 1 "Roller bench not detected" 2 "Not used" 3 "Roller bench detected" ;
VAL_ 695 ESC_HBB_Malfunction 0 "Fixed value transmitted" ;
VAL_ 695 HBAActive 0 "Fixed value transmitted" ;
VAL_ 695 EBDActive 0 "Fixed value transmitted" ;
VAL_ 144 MastervacPressureSensorNG 0 "Mastervac Pressure Sensor is OK" 1 "Mastervac Pressure Sensor is open circuit or short to GND " 2 "Mastervac Pressure Sensor is short to power supply circuit diagnosis NG" 3 "Mastervac Pressure Sensor is plausibility check diagnosis or power supply voltage" ;
VAL_ 697 CarSharingSteeringColumnUnlockAuthorization 0 "Fixed value transmitted" ;
VAL_ 697 IKeyCardDetectionRequest 0 "Fixed value transmitted" ;
VAL_ 697 CarSharingUserIdent 0 "Unavailable" 1 "External Reader" 2 "Call Center" 3 "Not Used" ;
VAL_ 697 CarSharingRequest 0 "No request" 1 "Lock Request" 2 "Unlock Request" 3 "Not used" ;
VAL_ 1098 FrontRoofState 0 "Front Roof fully open" 1 "Front Roof in conversion" 2 "Front Roof fully closed" 3 "Unavailable" ;
VAL_ 1098 RearRoofState 0 "Rear Roof fully open" 1 "Rear Roof in conversion" 2 "Rear Roof fully closed" 3 "Unavailable" ;
VAL_ 1098 CCM_Refuse_to_Sleep 0 "reserved" 1 "CCM refuse to sleep " 2 "CCM ready to sleep" 3 "reserved_3" ;
VAL_ 913 ClimateCoolingSelect 0 "Fixed value transmitted" ;
VAL_ 913 FrontDefrostRequest 0 "Fixed value transmitted" ;
VAL_ 913 ACVbatTempoMaintain 0 "Vbat Tempo Maintain for AC not requested" 1 "Vbat Tempo Maintain for AC requested" ;
VAL_ 913 PumpActivationRequest 0 "Fixed value transmitted" ;
VAL_ 1066 ComfortStateRequest 0 "Fixed value transmitted" ;
VAL_ 1066 PreHeatingCustomerRequest 0 "Fixed value transmitted" ;
VAL_ 1066 PreHeatingRequest 0 "PreHeating Not Requested" 1 "PreHeating Requested" ;
VAL_ 1066 ClimCustomerActivationStatus 0 "Reserved" 1 "AC ON" 2 "AC OFF" 3 "Unavailable" ;
VAL_ 1066 PTCActivationRequest 0 "Unavailable" 1 "CTP ON" 2 "CTP OFF" 3 "Not Used" ;
VAL_ 1066 ClimLoopMode 0 "Fixed value transmitted" ;
VAL_ 1066 PreheatingCustomerActivation 0 "Fixed value transmitted" ;
VAL_ 914 PumpActivationRequest 0 "Fixed value transmitted" ;
VAL_ 914 ACCompClutchStatus 0 "Fixed value transmitted" ;
VAL_ 914 AC_SailingIdleForbidden 1 "Fixed value transmitted" ;
VAL_ 914 FrontDefrostRequest 0 "Fixed value transmitted" ;
VAL_ 914 BatTempoDelayRequest_CLIM 0 "Fixed value transmitted" ;
VAL_ 914 ChillerActivationStatus 0 "No actived Valves " 1 "Actived Valves" 2 "Reserved" 3 "Unavailable" ;
VAL_ 1072 HVBatteryCoolingState 3 "Fixed value transmitted" ;
VAL_ 1072 ClimPanelPCActivationRequest 0 "No request" 1 "Pre heating time requested" 2 "Pre heating OFF requested" 3 "Unavailable" ;
VAL_ 1072 DeIcingRequest 3 "Fixed value transmitted" ;
VAL_ 1072 BatteryBlowerState 0 "Fixed value transmitted" ;
VAL_ 1272 OilDrainAlertResetRequest 0 "No OilDrainAlert reset requested" 1 "OilDrainAlert reset requested" ;
VAL_ 1272 FuelLow 0 "fuel level OK" 1 "fuel level low" ;
VAL_ 1272 HandBrakeSwitch 0 "not used" 1 "parking brake not applied" 2 "parking brake applied" 3 "unavailable" ;
VAL_ 1272 DiagnosedFuelLow 0 "Unavailable" 1 "Not empty" 2 "Empty" 3 "Not used" ;
VAL_ 1272 Cluster_Refuse_to_Sleep 0 "reserved" 1 "Cluster refuse to sleep " 2 "Cluster ready to sleep" 3 "reserved_3" ;
VAL_ 1272 MuteRadioOrder 0 "No mute radio order" 1 "Mute radio order" 2 "Not used" 3 "Not used_3" ;
VAL_ 1272 DisplayedSpeedUnit 0 "Speed Unit in kmph" 1 "Speed Unit in mph" ;
VAL_ 1272 ClusterDrivenLampsAutoCheck 0 "no self-test in progress" 1 "self-test in progress" ;
VAL_ 1272 PassAIRBAGInhibitionLampState 1 "Fixed value transmitted" ;
VAL_ 1272 AIRBAGMalfunctionLampState 0 "Diag result : AIRBAG Malfunction lamp OFF " 1 "Diag result : AIRBAG Malfunction lamp  ON " 2 "Diag result :  failure" 3 "Not used" ;
VAL_ 1272 BatteryChangedActivation 3 "Fixed value transmitted" ;
VAL_ 1272 PassAirbagONLampState 0 "Fixed value transmitted" ;
VAL_ 1272 DayNightStatusForB_Switches 0 "Conditionned backlight" 1 "Permanent backlight" ;
VAL_ 1272 DisplayFailure 0 "Unavailable" 1 "No display failure" 2 "Display failure" 3 "Not used" ;
VAL_ 1272 ACCDriverTakeOverDisplayAck 0 "Fixed value transmitted" ;
VAL_ 1272 ACCFrameMissing 0 "Fixed value transmitted" ;
VAL_ 1272 TachographPresence 0 "Fixed value transmitted" ;
VAL_ 1787 DisplayedOilLevel 0 "warning" 1 "1 bargraph element displayed" 2 "2 bargraph element displayed" 3 "3 bargraph element displayed" 4 "4 bargraph element displayed" 5 "5 bargraph element displayed" 6 "6 bargraph element displayed" 7 "7 bargraph element displayed" 8 "8 bargraph element displayed" 15 "not available" ;
VAL_ 1787 MILDisplayState 0 "Fixed value transmitted" ;
VAL_ 1787 ParticulateFilterWarningState 0 "Fixed value transmitted" ;
VAL_ 1787 BatteryWarningState 0 "Fixed value transmitted" ;
VAL_ 1787 WasherLevelWarningState 0 "Fixed value transmitted" ;
VAL_ 1787 GlobalVehicleWarningState 0 " No gloval  vehicle  Fault" 1 "SERV is ON (alert type R3)" 2 "STOP is ON (alert type D3)" 3 "SERV and STOP are ON (alert type R3& D3)" ;
VAL_ 1787 WaterInDieselWarningState 0 "Fixed value transmitted" ;
VAL_ 1787 BadgeWarningState 0 "Fixed value transmitted" ;
VAL_ 1787 MalfunctionLampWarningState 0 "Fixed value transmitted" ;
VAL_ 1622 PreHeatingTimeAcquisition 0 "Fixed value transmitted" ;
VAL_ 1622 TripDataReset 0 "Do not reset trip data" 1 "reset trip data" ;
VAL_ 1622 DisplayedSpeedUnit 0 "Speed Unit in kmph" 1 "Speed Unit in mph" ;
VAL_ 1622 RadarRecuperationActivation 0 "Turn RR OFF" 1 "Turn RR ON" 2 "Not Used" 3 "Unavailable" ;
VAL_ 1622 TripDataReset_2 0 "Do not reset trip data 2" 1 "reset trip data 2" ;
VAL_ 1622 SC_CustomerActiveTime2Request 0 "No request" 1 "SC deactivation requested for Precond Time 2" 2 "SC activation requested for Precond Time 2" 3 "Not used" ;
VAL_ 1622 SC_CustomerActiveTime1Request 0 "No request" 1 "SC deactivation requested for Precond Time 1" 2 "SC activation requested for Precond Time 1" 3 "Not used" ;
VAL_ 1622 ClimPCCustomerActiv 0 "No request" 1 "Pre heating time 1" 2 "Pre heating time 2" 3 "Pre Heating OFF request" ;
VAL_ 951 DayNightStatusForBacklights 0 "Day time according light level sensor and no light request from driver" 1 "Night time according to light level sensor or light requested by driver" ;
VAL_ 951 CruiseCtrlDeactivationforFailure 0 "Fixed value transmitted" ;
VAL_ 951 SteeringPhoneCommand 0 "Fixed value transmitted" ;
VAL_ 951 SteeringPushToTalkCommand 0 "Button released" 1 "Button pressed" ;
VAL_ 951 FCW_ActivationRequest 0 "no request " 1 "FCW activation requested " 2 "FCW deéactivation requested " 3 "unavailable" ;
VAL_ 951 ExternalTempDisplayUnit 0 "display mode in °C" 1 "display mode in °F" ;
VAL_ 951 EngineCoolantTempUnit 0 "Fixed value transmitted" ;
VAL_ 951 ClimTemperatureDisplayUnit 0 "Fixed value transmitted" ;
VAL_ 951 TPMS_ResetDriverRequest 0 "Unvailable Value" 1 "TPMS Reset driver NOT requested " 2 "TPMS Reset driver requested " 3 "Not Used" ;
VAL_ 1606 TripUnitDistance 0 "Km" 1 "Miles" 2 "not used" 3 "not used_3" ;
VAL_ 1606 TripUnitConsumption 0 "L / 100 km" 1 "Km / L" 2 "MPGus" 3 "MPGuk" 4 "KWh / 100 Km" 5 "KWh / 100 miles" 6 "MPGe (US)" 7 "MPGe (UK)" ;
VAL_ 1606 Cluster_ResetRequest 0 "Reset  CLUSTER not requested" 1 "Reset CLUSTER requested" ;
VAL_ 1606 LowOilPressureSwitch 0 "Fixed value transmitted" ;
VAL_ 1606 FrostWarningDisplay 0 "No alert" 1 "Frost warning Alert" ;
VAL_ 1606 AdvisorEcoLightingActivationState 0 "Unavailable " 1 "Advisor Econometer Lighting activated" 2 "Advisor Econometer Lighting deactivated" 3 "not used" ;
VAL_ 1486 UnitDistanceDisplayState 0 "displayed unit in km" 1 "displayed unit in mph" ;
VAL_ 1486 MeterLanguageKnowledge 0 "No Request" 1 "Requested language known" 2 "Requested language unknown" 3 "Not Used" ;
VAL_ 1486 AlertMinBeforeOverhaul 0 "No Alert " 1 "Time Prealert" 2 "Distance Prealert" 3 "Overhaul Alert" ;
VAL_ 1486 MeterLanguageStatus 0 "Unavailable value" ;
VAL_ 1577 ExternalTempFaultFlag 0 "No fault" 1 "High fault (shot circuit to Bat, open load)" 2 "Low fault (short circuit to ground)" 3 "Not Used" ;
VAL_ 1577 SteeringWheelVolumeDown 0 "Button released" 1 "Buttton pushed" ;
VAL_ 1577 SteeringWheelVolumeUp 0 "Button released" 1 "Buttton pushed" ;
VAL_ 1717 WAC_APRUN_ActivationRequest2 0 "Fixed value transmitted" ;
VAL_ 1717 IKeyAccessActivationRequest2 0 "Fixed value transmitted" ;
VAL_ 1717 AmbientLightingColorReq2 0 "Fixed value transmitted" ;
VAL_ 1717 BuzzerWAC_ActivationRequest2 0 "Fixed value transmitted" ;
VAL_ 1717 AmbientLightingPatternRequest2 0 "Fixed value transmitted" ;
VAL_ 1717 AutoLockUpActivationRequest2 0 "No Automatic Lock Up activation/ de-activation request" 1 "Automatic Lock Up activation request" 2 "Automatic lock up de-activation request" ;
VAL_ 1717 VehicleTrackingActivationRequest 0 "No Activation/Deactivation Request" 1 "Tracking Activation Request" 2 "Tracking Deactivation Request" 3 "Not used" ;
VAL_ 1717 SingleDoorOpeningActivationReq2 0 "No single door opening request" 1 "Single door opening activation requested" 2 "Single door opening de-activation requested" 3 "Reset Request" ;
VAL_ 1717 AutoRearWiperActivationRequest2 0 "No automatic rear wiper activation de-activation request" 1 "Automatic Rear wiper activation requested" 2 "Automatic Rear wiper de-activation requested" 3 "Reset request" ;
VAL_ 1075 AQMIoniserModeSelectionReq 0 "Fixed value transmitted" ;
VAL_ 1075 AQMFragDrawerUnlockRequest 0 "Fixed value transmitted" ;
VAL_ 1075 AQMFragSelectRequest 0 "Fixed value transmitted" ;
VAL_ 1075 ClimAQSActivationRequest 0 "No request" 1 "Activation request" 2 "No activation requested" 3 "Not used" ;
VAL_ 1075 AQMAutoRecyRequest 0 "Fixed value transmitted" ;
VAL_ 1075 AQMFragIntensityRequest 0 "Fixed value transmitted" ;
VAL_ 1075 MFD_ResetRequest 0 "Reset ADAC not requested" 1 "Reset ADAC requested" ;
VAL_ 1075 SC_ActivationTime2Display 0 "SC not activated for Precond Time 2" 1 "SC activated for Precond Time 2" ;
VAL_ 1075 SC_ActivationTime1Display 0 "SC not activated for Precond Time 1" 1 "SC activated for Precond Time 1" ;
VAL_ 1075 IoniserAutoLaunchRequest 0 "Fixed value transmitted" ;
VAL_ 1075 ChargingTimerRequest 0 "Fixed value transmitted" ;
VAL_ 1075 ClimPCMMCCustomerActiv 0 "Fixed value transmitted" ;
VAL_ 1075 SC_ActivationTime1Display_V2 3 "Fixed value transmitted" ;
VAL_ 1075 UserAcknowledgement 0 "Fixed value transmitted" ;
VAL_ 1075 HFP_SelectedManeuverTypeRequest 0 "Fixed value transmitted" ;
VAL_ 1075 SC_ActivationTime2Display_V2 3 "Fixed value transmitted" ;
VAL_ 502 EmissionN_IdleRequest 0 "Fixed value transmitted" ;
VAL_ 502 EngineFanSpeedRequest 0 "Fixed value transmitted" ;
VAL_ 502 EngineStopRequestOrigine 0 "No engine stop request (initial stop or independant engine running)" ;
VAL_ 502 EngineStatus_R 0 "engine stopped " 1 "Reserved" 2 " independant  running engine  " 3 "running engine-driven" ;
VAL_ 502 ElectricalPowerCutFreeze 0 "no request" 1 "PTC freeze request" 2 "PTC cut request" 3 "Reserved" ;
VAL_ 502 ACCompAuthorized 0 "ac compressor not authorized" 1 "ac compressor authorized" ;
VAL_ 502 N_IdleInstructionSignal 0 "Fixed value transmitted" ;
VAL_ 502 OpenActiveBrakeSwitch_ECM 0 "Fixed value transmitted" ;
VAL_ 502 ACCompClutchActivation 0 "Fixed value transmitted" ;
VAL_ 502 CrankingAuthorization_ECM 0 "cranking not allowed" 1 "cranking allowed" 2 "cranking stopped required" 3 "no request" ;
VAL_ 502 RST_RESERVED_2b 0 "Fixed value transmitted" ;
VAL_ 502 Reserved_2bits 0 "Fixed value transmitted" ;
VAL_ 502 DMSOrder 0 "Fixed value transmitted" ;
VAL_ 502 FloatingInhibition 0 "Fixed value transmitted" ;
VAL_ 1498 ECM_RearDefrostRequest 0 "Fixed value transmitted" ;
VAL_ 1498 ECM_MechanicalLoadRequest 0 "Fixed value transmitted" ;
VAL_ 1498 EngineCoolantRegulationTemp 0 "Fixed value transmitted" ;
VAL_ 1498 DownTransitionOfEngCoolantTemp 0 "No down transition in progress" 1 "Down transition in progress" ;
VAL_ 1498 GeneralDenominatorForTM 3 "Fixed value transmitted" ;
VAL_ 1498 EngOverSpeedCutOffThreshold 0 "low threshold" 1 "high threshold" ;
VAL_ 1498 EngineCoolantFlowStatus 0 "Unvailable Value" 1 "No EngineCoolantFlow" 2 "EngineCoolantFlow" 3 "Not Used" ;
VAL_ 535 VoltageRatebyECM 0 "No request" 1 "Rate 1" 2 "Rate 2" 3 "Rate 3" ;
VAL_ 535 ECM_StopAutoForbidden 0 "Fixed value transmitted" ;
VAL_ 535 PumpActivationRequest_ECM 0 "Fixed value transmitted" ;
VAL_ 535 ACCompClutchStatus_ECM 0 "Compressor clutch off" 1 "Compressor clutch on" ;
VAL_ 535 CoolingFanSpeedStatus 0 "Engine Fan Stopped" 1 "low speed engine fan active" 2 "mid speed engine fan active" 3 "high speed engine fan active" ;
VAL_ 535 ACCMainSwitchStatus 0 "Fixed value transmitted" ;
VAL_ 1628 EngineRearFanState 0 "rear fan activated" 1 "rear fan deactivated" ;
VAL_ 1628 ECM_StopAutoForbidden_v2 0 "Fixed value transmitted" ;
VAL_ 1053 AutoStartAuthorization 0 "Unavailable" 1 "Stop Start Authorized" 2 "Stop Start Not autjorized" 3 "Not Used" ;
VAL_ 1053 EngineStartRequest 0 "no engine start request " 1 "engine start request" ;
VAL_ 1053 EngineWarmUpPhase 0 "Fixed value transmitted" ;
VAL_ 1053 StopAutoPhase 0 "NotInAutoPhase" 1 "AutoStart" 2 "IdleStop" 3 "AutophaseAborted" 4 "Not Used" 5 "Not Used_5" 6 "Not Used_6" 7 "Unavailable" ;
VAL_ 1053 VoltageRegulationStatus 0 "not initialized" 1 "Starting Sequence" 2 "ECM is a simple Gate" 3 "power limitation" 4 "alternator communication fault is detected" 5 "alternator communication fault is confirmed" 6 "alternator fault is detected" 7 "alternator fault is confirmed" 8 "undervoltage is detected" 9 "undervoltage is confirmed" 10 "overvoltage is detected" 11 "overvoltage is confirmed" 12 "CAN communication fault from USM is detected in ECM" 13 "CAN communication fault from USM is confirmed in ECM" 14 "Not Used" 15 "unavailable value" ;
VAL_ 1053 Idle_Stop_Brake_Hold_Function_Request 0 "Fixed value transmitted" ;
VAL_ 1053 IG_OFF_DELAY_REQUEST 0 "Fixed value transmitted" ;
VAL_ 1053 Maintenance_Mode_Status 0 "not used" 1 "no request" 2 "request" 3 "unavailable" ;
VAL_ 1053 RollerBenchDisplay 0 "not present" 1 "Roller bench display requested" 2 "Roller bench display not requested" 3 "unavailable" ;
VAL_ 933 OBD_WUC 0 "Warm Up Cycle is NOT completed" 1 "Warm Up Cycle is completed" ;
VAL_ 933 OBD_GeneralTrip 0 "General Trip for PDTC clear is NOT completed" 1 "General Trip for PDTC clear is completed" ;
VAL_ 933 OBD_Engine_On 0 " Engine has NOT started" 1 " Engine has started" ;
VAL_ 529 IdleSpeedInhibitionRequest 0 "Fixed value transmitted" ;
VAL_ 529 IgnitionControlState 0 "Fixed value transmitted" ;
VAL_ 529 PositionLightsOmissionWarningEMM 0 "No position lights omission warning resquested" 1 "Position lights omission warning requested" 2 "not used" 3 "reserved" ;
VAL_ 529 EMM_Refuse_to_Sleep 0 "reserved" 1 "EMM refuse to sleep " 2 "EMM ready to sleep" 3 "reserved_3" ;
VAL_ 529 FrontWiperStatus 0 "unvailable value" 1 "front wiper stopped" 2 "front wiper activ" 3 "not used" ;
VAL_ 529 EngineStopAutoWarnStatus 0 "Fixed value transmitted" ;
VAL_ 529 RemoteLightingRequest 0 "Fixed value transmitted" ;
VAL_ 529 LowBeamDisplayEMM 0 "low beam display not requested" 1 "low beam display requested" ;
VAL_ 529 HighBeamDisplayEMM 0 "High beam display not requested" 1 "High beam display requested" ;
VAL_ 529 PositionLightsDisplayEMM 0 "position lights display not requested" 1 "position lights display requested" ;
VAL_ 529 FrontFogLightsDisplayEMM 0 "front fog lights display not requested" 1 "front fog lights display requested" ;
VAL_ 529 RearFogLightStateDisplayEMM 0 "rear fog light OFF" 1 "rear fog light ON" ;
VAL_ 529 EMM_DayNightStatusSynthesis 0 "Day Mode" 1 "Night Mode" 2 "Not used" 3 "Unavailable" ;
VAL_ 529 MiniConsumptionRequest 1 "Fixed value transmitted" ;
VAL_ 532 LightSensorStatus 0 "Day time according light level sensor " 1 "Night time according to light level sensor" ;
VAL_ 1580 EPSCityModeActivationDisplay 0 "No EPS City Mode activation display requested " 1 "EPS City Mode activation display requested" ;
VAL_ 1580 EPSWarning 0 "No EPS warning" 1 "EPS failure level 1" 2 "EPS failure level 2" 3 "Not Used" ;
VAL_ 811 FCWWarning_Request 0 "No warning" 1 "Warning level 1" 2 "Warning Level 2" 3 "Not used" ;
VAL_ 811 FCWFailure_Status 0 "FCW Failure" 1 "No FCW Failure" ;
VAL_ 811 FCW_NewObjectDetected 0 "No new object detected" 1 "new object detected" ;
VAL_ 811 FCW_MovingObjectStatus 0 "No object" 1 "Moving object" 2 "Moving-stationary object" 3 "Stationary object" 4 "Not Used" 5 "Not Used_5" 6 "Not Used_6" 7 "unavailable" ;
VAL_ 811 FCW_SystemStatus 0 "System OK" 1 "System temporarily unavailable" 2 "System permanently unavailable" 3 "Unavailable" ;
VAL_ 1737 HVBatEndOfChargeTrigger 0 "Fixed value transmitted" ;
VAL_ 1737 HVBatStartOfChargeTrigger 0 "Fixed value transmitted" ;
VAL_ 1360 MVC_ViewModeRequest 0 "Fixed value transmitted" ;
VAL_ 1360 StorageFormatRequest 0 "Fixed value transmitted" ;
VAL_ 1360 Audio_WakeUpSleepCommand 3 "Fixed value transmitted" ;
VAL_ 1360 BlowerReductionRequest 0 "Blower Speed Reduction not Requested" 1 "Blower Speed Reduction Requested" ;
VAL_ 1360 DataWipeStatus 0 "No Data Wipe" 1 "Data Wipe done" 2 "Reserved" 3 "Reserved_3" ;
VAL_ 1360 Audio_ProcessingDeactivation 0 "Fixed value transmitted" ;
VAL_ 1360 IVI_RefusetoSleep 0 "reserved" 1 "IVI refuse to sleep" 2 "IVI ready to sleep" 3 "reserved_3" ;
VAL_ 1360 RESFuelBurnerActivation 0 "Fixed value transmitted" ;
VAL_ 1360 AudioLanguageStatus 0 "Unavailable value" ;
VAL_ 1781 ChargeCal5TuesdayChange_MMI 0 "Unselected day" 1 "Selected day" ;
VAL_ 1781 ChargeCal5MondayChange_MMI 0 "Unselected day" 1 "Selected day" ;
VAL_ 1781 ChargeCal5SundayChange_MMI 0 "Unselected day" 1 "Selected day" ;
VAL_ 1781 ChargeCal5SaturdayChange_MMI 0 "Unselected day" 1 "Selected day" ;
VAL_ 1781 ChargeCal5FridayChange_MMI 0 "Unselected day" 1 "Selected day" ;
VAL_ 1781 ChargeCal5ThursdayChange_MMI 0 "Unselected day" 1 "Selected day" ;
VAL_ 1781 ChargeCal5WednesdayChange_MMI 0 "Unselected day" 1 "Selected day" ;
VAL_ 1781 EcoTripResetRequest 0 "Fixed value transmitted" ;
VAL_ 1781 ChargeDelayedRequest 0 "No request" 1 "Delayed charge request" ;
VAL_ 1781 ChargeAlwaysRequest 0 "No request" 1 "Always charge request" ;
VAL_ 1781 MVC_ViewModeRequest 0 "Fixed value transmitted" ;
VAL_ 1781 SC_UserElecPriceSetRelativeCost 0 "Fixed value transmitted" ;
VAL_ 1781 FuelSaveClearHistoRequest 0 "Fixed value transmitted" ;
VAL_ 1782 PreSoakCal1FridayChange_MMI 0 "Unselected day" 1 "Selected day" ;
VAL_ 1782 PreSoakCal1ThursdayChange_MMI 0 "Unselected day" 1 "Selected day" ;
VAL_ 1782 PreSoakCal1WednesdayChange_MMI 0 "Unselected day" 1 "Selected day" ;
VAL_ 1782 PreSoakCal1TuesdayChange_MMI 0 "Unselected day" 1 "Selected day" ;
VAL_ 1782 PreSoakCal1MondayChange_MMI 0 "Unselected day" 1 "Selected day" ;
VAL_ 1782 PreSoakCal1SundayChange_MMI 0 "Unselected day" 1 "Selected day" ;
VAL_ 1782 PreSoakCal1SaturdayChange_MMI 0 "Unselected day" 1 "Selected day" ;
VAL_ 1782 PreSoakCal2WednesdayChange_MMI 0 "Unselected day" 1 "Selected day" ;
VAL_ 1782 PreSoakCal2TuesdayChange_MMI 0 "Unselected day" 1 "Selected day" ;
VAL_ 1782 PreSoakCal2MondayChange_MMI 0 "Unselected day" 1 "Selected day" ;
VAL_ 1782 PreSoakCal2SundayChange_MMI 0 "Unselected day" 1 "Selected day" ;
VAL_ 1782 PreSoakCal2SaturdayChange_MMI 0 "Unselected day" 1 "Selected day" ;
VAL_ 1782 PreSoakCal2FridayChange_MMI 0 "Unselected day" 1 "Selected day" ;
VAL_ 1782 PreSoakCal2ThursdayChange_MMI 0 "Unselected day" 1 "Selected day" ;
VAL_ 1782 PreSoakCal3MondayChange_MMI 0 "Unselected day" 1 "Selected day" ;
VAL_ 1782 PreSoakCalAllChange_MMI 0 "No Request" 1 "Change all presoak calendars request" 2 "Reset all presoak calendars request" 3 "Not used" ;
VAL_ 1782 PreSoakCal3SundayChange_MMI 0 "Unselected day" 1 "Selected day" ;
VAL_ 1782 PreSoakCal3SaturdayChange_MMI 0 "Unselected day" 1 "Selected day" ;
VAL_ 1782 PreSoakCal3FridayChange_MMI 0 "Unselected day" 1 "Selected day" ;
VAL_ 1782 PreSoakCal3ThursdayChange_MMI 0 "Unselected day" 1 "Selected day" ;
VAL_ 1782 PreSoakCal3WednesdayChange_MMI 0 "Unselected day" 1 "Selected day" ;
VAL_ 1782 PreSoakCal3TuesdayChange_MMI 0 "Unselected day" 1 "Selected day" ;
VAL_ 1783 PreSoakCal4FridayChange_MMI 0 "Unselected day" 1 "Selected day" ;
VAL_ 1783 PreSoakCal4ThursdayChange_MMI 0 "Unselected day" 1 "Selected day" ;
VAL_ 1783 PreSoakCal4WednesdayChange_MMI 0 "Unselected day" 1 "Selected day" ;
VAL_ 1783 PreSoakCal4TuesdayChange_MMI 0 "Unselected day" 1 "Selected day" ;
VAL_ 1783 PreSoakCal4MondayChange_MMI 0 "Unselected day" 1 "Selected day" ;
VAL_ 1783 PreSoakCal4SundayChange_MMI 0 "Unselected day" 1 "Selected day" ;
VAL_ 1783 PreSoakCal4SaturdayChange_MMI 0 "Unselected day" 1 "Selected day" ;
VAL_ 1783 PreSoakCal5WednesdayChange_MMI 0 "Unselected day" 1 "Selected day" ;
VAL_ 1783 PreSoakCal5TuesdayChange_MMI 0 "Unselected day" 1 "Selected day" ;
VAL_ 1783 PreSoakCal5MondayChange_MMI 0 "Unselected day" 1 "Selected day" ;
VAL_ 1783 PreSoakCal5SundayChange_MMI 0 "Unselected day" 1 "Selected day" ;
VAL_ 1783 PreSoakCal5SaturdayChange_MMI 0 "Unselected day" 1 "Selected day" ;
VAL_ 1783 PreSoakCal5FridayChange_MMI 0 "Unselected day" 1 "Selected day" ;
VAL_ 1783 PreSoakCal5ThursdayChange_MMI 0 "Unselected day" 1 "Selected day" ;
VAL_ 1779 ChargeCal1TuesdayChange_MMI 0 "Unselected day" 1 "Selected day" ;
VAL_ 1779 ChargeCal1MondayChange_MMI 0 "Unselected day" 1 "Selected day" ;
VAL_ 1779 ChargeCal1SundayChange_MMI 0 "Unselected day" 1 "Selected day" ;
VAL_ 1779 ChargeCal1SaturdayChange_MMI 0 "Unselected day" 1 "Selected day" ;
VAL_ 1779 ChargeCal1FridayChange_MMI 0 "Unselected day" 1 "Selected day" ;
VAL_ 1779 ChargeCal1ThursdayChange_MMI 0 "Unselected day" 1 "Selected day" ;
VAL_ 1779 ChargeCal1WednesdayChange_MMI 0 "Unselected day" 1 "Selected day" ;
VAL_ 1779 ChargeCal2TuesdayChange_MMI 0 "Unselected day" 1 "Selected day" ;
VAL_ 1779 ChargeCal2MondayChange_MMI 0 "Unselected day" 1 "Selected day" ;
VAL_ 1779 ChargeCalAllChange_MMI 0 "No Request" 1 "Change all charge calendars request" 2 "Reset all charge calendars request" 3 "Not used" ;
VAL_ 1779 ChargeCal2SundayChange_MMI 0 "Unselected day" 1 "Selected day" ;
VAL_ 1779 ChargeCal2SaturdayChange_MMI 0 "Unselected day" 1 "Selected day" ;
VAL_ 1779 ChargeCal2FridayChange_MMI 0 "Unselected day" 1 "Selected day" ;
VAL_ 1779 ChargeCal2ThursdayChange_MMI 0 "Unselected day" 1 "Selected day" ;
VAL_ 1779 ChargeCal2WednesdayChange_MMI 0 "Unselected day" 1 "Selected day" ;
VAL_ 1780 ChargeCal3TuesdayChange_MMI 0 "Unselected day" 1 "Selected day" ;
VAL_ 1780 ChargeCal3MondayChange_MMI 0 "Unselected day" 1 "Selected day" ;
VAL_ 1780 ChargeCal3SundayChange_MMI 0 "Unselected day" 1 "Selected day" ;
VAL_ 1780 ChargeCal3SaturdayChange_MMI 0 "Unselected day" 1 "Selected day" ;
VAL_ 1780 ChargeCal3FridayChange_MMI 0 "Unselected day" 1 "Selected day" ;
VAL_ 1780 ChargeCal3ThursdayChange_MMI 0 "Unselected day" 1 "Selected day" ;
VAL_ 1780 ChargeCal3WednesdayChange_MMI 0 "Unselected day" 1 "Selected day" ;
VAL_ 1780 ChargeCal4TuesdayChange_MMI 0 "Unselected day" 1 "Selected day" ;
VAL_ 1780 ChargeCal4MondayChange_MMI 0 "Unselected day" 1 "Selected day" ;
VAL_ 1780 ChargeCal4SundayChange_MMI 0 "Unselected day" 1 "Selected day" ;
VAL_ 1780 ChargeCal4SaturdayChange_MMI 0 "Unselected day" 1 "Selected day" ;
VAL_ 1780 ChargeCal4FridayChange_MMI 0 "Unselected day" 1 "Selected day" ;
VAL_ 1780 ChargeCal4ThursdayChange_MMI 0 "Unselected day" 1 "Selected day" ;
VAL_ 1780 ChargeCal4WednesdayChange_MMI 0 "Unselected day" 1 "Selected day" ;
